AUTOSAR XML (schema 00048)
package /VehicleProject
  system System
package /Diagnostics
  diagnostic service table DS_ABT_1_MIB_ab_Gen3: ecu-instance=ABT_1_MIB_ab_Gen3
    diagnostic-connections:
      DC_DIA_ABT_1_oABT_1_MIB_ab_Gen3_oMIBCAN
      DC_Diag_ABT_1_oABT_1_MIB_ab_Gen3_oMIBCAN
      DC_HID_ABT_1_ZR_oICC_IO_Node_oMIBCAN
      {diagnostic-connection=DC_HID_ABT_1_ZR_oZR_MIB_EINSTIEG_ab_Gen3_oMIBCAN, variation-point=post-build-variant-condition{matching-criterion=Communication, value=0}}
      {diagnostic-connection=DC_HID_ABT_1_ZR_oZR_MIB_OPTION_ab_Gen3_oMIBCAN, variation-point=post-build-variant-condition{matching-criterion=Communication, value=0}}
      DC_HID_ZR_ABT_1_oABT_1_MIB_ab_Gen3_oMIBCAN
      DC_KS_SSN_ABT_1_oABT_1_MIB_ab_Gen3_oMIBCAN
      DC_OBDC_SSN_ABT_1_oABT_1_MIB_ab_Gen3_oMIBCAN
      {diagnostic-connection=DC_HID_ABT_1_ZR_oICAS3_Gateway_oMIBCAN, variation-point=post-build-variant-condition{matching-criterion=Communication, value=1}}
      {diagnostic-connection=DC_HID_ABT_1_ZR_oZR_MIB_TOP_ab_Gen3_oMIBCAN, variation-point=post-build-variant-condition{matching-criterion=Communication, value=1}}
  10 x diagnostic connection:
    DC_DIA_ABT_1_oABT_1_MIB_ab_Gen3_oMIBCAN: physical-request=MIBCAN/DIA_ABT_1_Req_oTN_ABT_1_MIB_ab_Gen3, response=MIBCAN/DIA_ABT_1_Resp_oTN_ABT_1_MIB_ab_Gen3
    DC_Diag_ABT_1_oABT_1_MIB_ab_Gen3_oMIBCAN: physical-request=MIBCAN/Diag_ABT_1_Req_oTN_ABT_1_MIB_ab_Gen3, response=MIBCAN/Diag_ABT_1_Resp_oTN_ABT_1_MIB_ab_Gen3
    DC_HID_ABT_1_ZR_oICC_IO_Node_oMIBCAN: physical-request=MIBCAN/HID_ABT_1_ZR_Req_oTN_ICC_IO_Node, response=MIBCAN/HID_ABT_1_ZR_Resp_oTN_ICC_IO_Node
    DC_HID_ABT_1_ZR_oZR_MIB_EINSTIEG_ab_Gen3_oMIBCAN: physical-request=HID_ABT_1_ZR_Req_oTN_ZR_MIB_EINSTIEG_ab_Gen3, response=HID_ABT_1_ZR_Resp_oTN_ZR_MIB_EINSTIEG_ab_Gen3
    DC_HID_ABT_1_ZR_oZR_MIB_OPTION_ab_Gen3_oMIBCAN: physical-request=HID_ABT_1_ZR_Req_oTN_ZR_MIB_OPTION_ab_Gen3, response=HID_ABT_1_ZR_Resp_oTN_ZR_MIB_OPTION_ab_Gen3
    DC_HID_ZR_ABT_1_oABT_1_MIB_ab_Gen3_oMIBCAN: physical-request=MIBCAN/HID_ZR_ABT_1_Req_oTN_ABT_1_MIB_ab_Gen3, response=MIBCAN/HID_ZR_ABT_1_Resp_oTN_ABT_1_MIB_ab_Gen3
    DC_KS_SSN_ABT_1_oABT_1_MIB_ab_Gen3_oMIBCAN: physical-request=MIBCAN/KS_SSN_ABT_1_Req_oTN_ABT_1_MIB_ab_Gen3, response=MIBCAN/KS_SSN_ABT_1_Resp_oTN_ABT_1_MIB_ab_Gen3
    DC_OBDC_SSN_ABT_1_oABT_1_MIB_ab_Gen3_oMIBCAN: physical-request=MIBCAN/OBDC_SSN_ABT_1_Req_oTN_ABT_1_MIB_ab_Gen3, response=MIBCAN/OBDC_SSN_ABT_1_Resp_oTN_ABT_1_MIB_ab_Gen3
    DC_HID_ABT_1_ZR_oICAS3_Gateway_oMIBCAN: physical-request=HID_ABT_1_ZR_Req_oTN_ICAS3_Gateway, response=HID_ABT_1_ZR_Resp_oTN_ICAS3_Gateway
    DC_HID_ABT_1_ZR_oZR_MIB_TOP_ab_Gen3_oMIBCAN: physical-request=HID_ABT_1_ZR_Req_oTN_ZR_MIB_TOP_ab_Gen3, response=HID_ABT_1_ZR_Resp_oTN_ZR_MIB_TOP_ab_Gen3
package /NM
  nm config NmConfig: can-nm-cluster-coupling=coupled-cluster=MIBCAN
    can nm cluster MIBCAN: communication-cluster=MIBCAN, nm-channel-id=0, nm-cbv-position=1, nm-network-timeout=1, nm-nid-position=0, nm-user-data-length=6, nm-wait-bus-sleep-time=0.75
      22 x can nm node, all with nm-range-config={lower-can-id=452984832, upper-can-id=452985087}:
        ABT_1_MIB_ab_Gen3: controller=CT_MIBCAN, nm-if-ecu=ABT_1_MIB_ab_Gen3_CAN, nm-node-id=241, rx-nm-pdu=[NMH_DU_1_oMIBCAN, NMH_DU_2_oMIBCAN, NMH_Info_El_oMIBCAN, NMH_LSR_1_oMIBCAN, NMH_WLC1_oMIBCAN], tx-nm-pdu=NMH_ABT_1_oMIBCAN, variation-point=post-build-variant-condition{matching-criterion=Communication, value=0}
        DU_1_MQB: nm-if-ecu=DU_1_MQB_CAN, nm-node-id=242, rx-nm-pdu=[NMH_ABT_1_oMIBCAN, NMH_DU_2_oMIBCAN, NMH_Info_El_oMIBCAN, NMH_LSR_1_oMIBCAN, NMH_WLC1_oMIBCAN], tx-nm-pdu=NMH_DU_1_oMIBCAN, variation-point=post-build-variant-condition{matching-criterion=Communication, value=0}
        DU_2: nm-if-ecu=DU_2_CAN, nm-node-id=245, rx-nm-pdu=[NMH_ABT_1_oMIBCAN, NMH_DU_1_oMIBCAN, NMH_Info_El_oMIBCAN, NMH_LSR_1_oMIBCAN, NMH_WLC1_oMIBCAN], tx-nm-pdu=NMH_DU_2_oMIBCAN, variation-point=post-build-variant-condition{matching-criterion=Communication, value=0}
        ICC_IO_Node: nm-if-ecu=ICC_IO_Node_CAN, nm-node-id=115, rx-nm-pdu=[NMH_ABT_1_oMIBCAN, NMH_DU_1_oMIBCAN, NMH_DU_2_oMIBCAN, NMH_LSR_1_oMIBCAN, NMH_WLC1_oMIBCAN], tx-nm-pdu=NMH_Info_El_oMIBCAN, variation-point=post-build-variant-condition{matching-criterion=Communication, value=0}
        LSR_1: nm-if-ecu=LSR_1_CAN, nm-node-id=246, rx-nm-pdu=[NMH_ABT_1_oMIBCAN, NMH_DU_1_oMIBCAN, NMH_DU_2_oMIBCAN, NMH_Info_El_oMIBCAN, NMH_WLC1_oMIBCAN], tx-nm-pdu=NMH_LSR_1_oMIBCAN, variation-point=post-build-variant-condition{matching-criterion=Communication, value=0}
        Sound_MIB_ab_Gen3: nm-if-ecu=Sound_MIB_ab_Gen3_CAN, nm-node-id=0, nm-passive-mode-enabled=true, rx-nm-pdu=[NMH_ABT_1_oMIBCAN, NMH_DU_1_oMIBCAN, NMH_DU_2_oMIBCAN, NMH_Info_El_oMIBCAN, NMH_LSR_1_oMIBCAN, NMH_WLC1_oMIBCAN], variation-point=post-build-variant-condition{matching-criterion=Communication, value=0}
        TVTuner_ab_Gen3_JPN: nm-if-ecu=TVTuner_ab_Gen3_JPN_CAN, nm-node-id=0, nm-passive-mode-enabled=true, rx-nm-pdu=[NMH_ABT_1_oMIBCAN, NMH_DU_1_oMIBCAN, NMH_DU_2_oMIBCAN, NMH_Info_El_oMIBCAN, NMH_LSR_1_oMIBCAN, NMH_WLC1_oMIBCAN], variation-point=post-build-variant-condition{matching-criterion=Communication, value=0}
        WLC_01: nm-if-ecu=WLC_01_CAN, nm-node-id=165, rx-nm-pdu=[NMH_ABT_1_oMIBCAN, NMH_DU_1_oMIBCAN, NMH_DU_2_oMIBCAN, NMH_Info_El_oMIBCAN, NMH_LSR_1_oMIBCAN], tx-nm-pdu=NMH_WLC1_oMIBCAN, variation-point=post-build-variant-condition{matching-criterion=Communication, value=0}
        ZR_MIB_EINSTIEG_ab_Gen3: nm-if-ecu=ZR_MIB_EINSTIEG_ab_Gen3_CAN, nm-node-id=115, rx-nm-pdu=[NMH_ABT_1_oMIBCAN, NMH_DU_1_oMIBCAN, NMH_DU_2_oMIBCAN, NMH_LSR_1_oMIBCAN, NMH_WLC1_oMIBCAN], tx-nm-pdu=NMH_Info_El_oMIBCAN, variation-point=post-build-variant-condition{matching-criterion=Communication, value=0}
        ZR_MIB_OPTION_ab_Gen3: nm-if-ecu=ZR_MIB_OPTION_ab_Gen3_CAN, nm-node-id=115, rx-nm-pdu=[NMH_ABT_1_oMIBCAN, NMH_DU_1_oMIBCAN, NMH_DU_2_oMIBCAN, NMH_LSR_1_oMIBCAN, NMH_WLC1_oMIBCAN], tx-nm-pdu=NMH_Info_El_oMIBCAN, variation-point=post-build-variant-condition{matching-criterion=Communication, value=0}
        ZR_MIB_TOP_ab_Gen3: nm-if-ecu=ZR_MIB_TOP_ab_Gen3_CAN, nm-node-id=115, rx-nm-pdu=[NMH_ABT_1_oMIBCAN, NMH_DU_1_oMIBCAN, NMH_DU_2_oMIBCAN, NMH_LSR_1_oMIBCAN, NMH_WLC1_oMIBCAN], tx-nm-pdu=NMH_Info_El_oMIBCAN, variation-point=post-build-variant-condition{matching-criterion=Communication, value=0}
        ABT_1_MIB_ab_Gen3: controller=CT_MIBCAN, nm-if-ecu=ABT_1_MIB_ab_Gen3_CAN, nm-node-id=241, rx-nm-pdu=[NMH_DU_1_oMIBCAN, NMH_DU_2_oMIBCAN, NMH_DU_3_oMIBCAN, NMH_Info_El_oMIBCAN, NMH_LSR_1_oMIBCAN, NMH_WLC1_oMIBCAN], tx-nm-pdu=NMH_ABT_1_oMIBCAN, variation-point=post-build-variant-condition{matching-criterion=Communication, value=1}
        DU_1_MQB: nm-if-ecu=DU_1_MQB_CAN, nm-node-id=242, rx-nm-pdu=[NMH_ABT_1_oMIBCAN, NMH_DU_2_oMIBCAN, NMH_DU_3_oMIBCAN, NMH_Info_El_oMIBCAN, NMH_LSR_1_oMIBCAN, NMH_WLC1_oMIBCAN], tx-nm-pdu=NMH_DU_1_oMIBCAN, variation-point=post-build-variant-condition{matching-criterion=Communication, value=1}
        DU_2: nm-if-ecu=DU_2_CAN, nm-node-id=245, rx-nm-pdu=[NMH_ABT_1_oMIBCAN, NMH_DU_1_oMIBCAN, NMH_DU_3_oMIBCAN, NMH_Info_El_oMIBCAN, NMH_LSR_1_oMIBCAN, NMH_WLC1_oMIBCAN], tx-nm-pdu=NMH_DU_2_oMIBCAN, variation-point=post-build-variant-condition{matching-criterion=Communication, value=1}
        DU_3: nm-if-ecu=DU_3_CAN, nm-node-id=254, rx-nm-pdu=[NMH_ABT_1_oMIBCAN, NMH_DU_1_oMIBCAN, NMH_DU_2_oMIBCAN, NMH_Info_El_oMIBCAN, NMH_LSR_1_oMIBCAN, NMH_WLC1_oMIBCAN], tx-nm-pdu=NMH_DU_3_oMIBCAN, variation-point=post-build-variant-condition{matching-criterion=Communication, value=1}
        ICAS3_Gateway: nm-if-ecu=ICAS3_Gateway_CAN, nm-node-id=115, rx-nm-pdu=[NMH_ABT_1_oMIBCAN, NMH_DU_1_oMIBCAN, NMH_DU_2_oMIBCAN, NMH_DU_3_oMIBCAN, NMH_LSR_1_oMIBCAN, NMH_WLC1_oMIBCAN], tx-nm-pdu=NMH_Info_El_oMIBCAN, variation-point=post-build-variant-condition{matching-criterion=Communication, value=1}
        ICC_IO_Node: nm-if-ecu=ICC_IO_Node_CAN, nm-node-id=115, rx-nm-pdu=[NMH_ABT_1_oMIBCAN, NMH_DU_1_oMIBCAN, NMH_DU_2_oMIBCAN, NMH_DU_3_oMIBCAN, NMH_LSR_1_oMIBCAN, NMH_WLC1_oMIBCAN], tx-nm-pdu=NMH_Info_El_oMIBCAN, variation-point=post-build-variant-condition{matching-criterion=Communication, value=1}
        LSR_1: nm-if-ecu=LSR_1_CAN, nm-node-id=246, rx-nm-pdu=[NMH_ABT_1_oMIBCAN, NMH_DU_1_oMIBCAN, NMH_DU_2_oMIBCAN, NMH_DU_3_oMIBCAN, NMH_Info_El_oMIBCAN, NMH_WLC1_oMIBCAN], tx-nm-pdu=NMH_LSR_1_oMIBCAN, variation-point=post-build-variant-condition{matching-criterion=Communication, value=1}
        Sound_MIB_ab_Gen3: nm-if-ecu=Sound_MIB_ab_Gen3_CAN, nm-node-id=0, nm-passive-mode-enabled=true, rx-nm-pdu=[NMH_ABT_1_oMIBCAN, NMH_DU_1_oMIBCAN, NMH_DU_2_oMIBCAN, NMH_DU_3_oMIBCAN, NMH_Info_El_oMIBCAN, NMH_LSR_1_oMIBCAN, NMH_WLC1_oMIBCAN], variation-point=post-build-variant-condition{matching-criterion=Communication, value=1}
        TVTuner_ab_Gen3_JPN: nm-if-ecu=TVTuner_ab_Gen3_JPN_CAN, nm-node-id=0, nm-passive-mode-enabled=true, rx-nm-pdu=[NMH_ABT_1_oMIBCAN, NMH_DU_1_oMIBCAN, NMH_DU_2_oMIBCAN, NMH_DU_3_oMIBCAN, NMH_Info_El_oMIBCAN, NMH_LSR_1_oMIBCAN, NMH_WLC1_oMIBCAN], variation-point=post-build-variant-condition{matching-criterion=Communication, value=1}
        WLC_01: nm-if-ecu=WLC_01_CAN, nm-node-id=165, rx-nm-pdu=[NMH_ABT_1_oMIBCAN, NMH_DU_1_oMIBCAN, NMH_DU_2_oMIBCAN, NMH_DU_3_oMIBCAN, NMH_Info_El_oMIBCAN, NMH_LSR_1_oMIBCAN], tx-nm-pdu=NMH_WLC1_oMIBCAN, variation-point=post-build-variant-condition{matching-criterion=Communication, value=1}
        ZR_MIB_TOP_ab_Gen3: nm-if-ecu=ZR_MIB_TOP_ab_Gen3_CAN, nm-node-id=115, rx-nm-pdu=[NMH_ABT_1_oMIBCAN, NMH_DU_1_oMIBCAN, NMH_DU_2_oMIBCAN, NMH_DU_3_oMIBCAN, NMH_LSR_1_oMIBCAN, NMH_WLC1_oMIBCAN], tx-nm-pdu=NMH_Info_El_oMIBCAN, variation-point=post-build-variant-condition{matching-criterion=Communication, value=1}
    nm-if-ecus:
      13 x nm ecu, all with nm-node-id-enabled=true, nm-user-data-enabled=true:
        ABT_1_MIB_ab_Gen3_CAN: ecu-instance=ABT_1_MIB_ab_Gen3
        DU_1_MQB_CAN
        DU_2_CAN
        ICC_IO_Node_CAN
        LSR_1_CAN
        Sound_MIB_ab_Gen3_CAN: nm-passive-mode-enabled=true
        TVTuner_ab_Gen3_JPN_CAN: nm-passive-mode-enabled=true
        WLC_01_CAN
        ZR_MIB_EINSTIEG_ab_Gen3_CAN: variation-point=post-build-variant-condition{matching-criterion=Communication, value=0}
        ZR_MIB_OPTION_ab_Gen3_CAN: variation-point=post-build-variant-condition{matching-criterion=Communication, value=0}
        ZR_MIB_TOP_ab_Gen3_CAN
        DU_3_CAN: variation-point=post-build-variant-condition{matching-criterion=Communication, value=1}
        ICAS3_Gateway_CAN: variation-point=post-build-variant-condition{matching-criterion=Communication, value=1}
package /TP
  can tp config MIBCAN: communication-cluster=MIBCAN, can-tp-ecu{cycle-time-main-function=0.005, ecu-instance=ABT_1_MIB_ab_Gen3}
    can tp channel TPCH: channel-id=0, channel-mode=FULL-DUPLEX-MODE
    can-tp-connection addressing-format=STANDARD, can-tp-channel=TPCH, data-pdu=DIA_ABT_1_Req_Tp_oMIBCAN, flow-control-pdu=DIA_ABT_1_Resp_Tp_oMIBCAN, receiver=TN_ABT_1_MIB_ab_Gen3, ta-type=PHYSICAL, tp-sdu=DIA_ABT_1_Req_oMIBCAN, transmitter=TN_ICC_IO_Node, variation-point=post-build-variant-condition{matching-criterion=Communication, value=0}:
      ident DIA_ABT_1_Req_oTN_ABT_1_MIB_ab_Gen3
    can-tp-connection addressing-format=STANDARD, can-tp-channel=TPCH, data-pdu=DIA_ABT_1_Resp_Tp_oMIBCAN, flow-control-pdu=DIA_ABT_1_Req_Tp_oMIBCAN, receiver=TN_ICC_IO_Node, ta-type=PHYSICAL, tp-sdu=DIA_ABT_1_Resp_oMIBCAN, transmitter=TN_ABT_1_MIB_ab_Gen3, variation-point=post-build-variant-condition{matching-criterion=Communication, value=0}:
      ident DIA_ABT_1_Resp_oTN_ABT_1_MIB_ab_Gen3
    can-tp-connection addressing-format=STANDARD, can-tp-channel=TPCH, data-pdu=Diag_ABT_1_Req_Tp_oMIBCAN, flow-control-pdu=Diag_ABT_1_Resp_Tp_oMIBCAN, receiver=TN_ABT_1_MIB_ab_Gen3, ta-type=PHYSICAL, tp-sdu=Diag_ABT_1_Req_oMIBCAN, transmitter=TN_ICC_IO_Node, variation-point=post-build-variant-condition{matching-criterion=Communication, value=0}:
      ident Diag_ABT_1_Req_oTN_ABT_1_MIB_ab_Gen3
    can-tp-connection addressing-format=STANDARD, can-tp-channel=TPCH, data-pdu=Diag_ABT_1_Resp_Tp_oMIBCAN, flow-control-pdu=Diag_ABT_1_Req_Tp_oMIBCAN, receiver=TN_ICC_IO_Node, ta-type=PHYSICAL, tp-sdu=Diag_ABT_1_Resp_oMIBCAN, transmitter=TN_ABT_1_MIB_ab_Gen3, variation-point=post-build-variant-condition{matching-criterion=Communication, value=0}:
      ident Diag_ABT_1_Resp_oTN_ABT_1_MIB_ab_Gen3
    can-tp-connection addressing-format=STANDARD, can-tp-channel=TPCH, data-pdu=HID_ABT_1_ZR_Req_Tp_oMIBCAN, flow-control-pdu=HID_ABT_1_ZR_Resp_Tp_oMIBCAN, receiver=TN_ICC_IO_Node, ta-type=PHYSICAL, tp-sdu=HID_ABT_1_ZR_Req_oMIBCAN, transmitter=TN_ABT_1_MIB_ab_Gen3, variation-point=post-build-variant-condition{matching-criterion=Communication, value=0}:
      ident HID_ABT_1_ZR_Req_oTN_ICC_IO_Node
    can-tp-connection addressing-format=STANDARD, can-tp-channel=TPCH, data-pdu=HID_ABT_1_ZR_Req_Tp_oMIBCAN, flow-control-pdu=HID_ABT_1_ZR_Resp_Tp_oMIBCAN, receiver=TN_ZR_MIB_EINSTIEG_ab_Gen3, ta-type=PHYSICAL, tp-sdu=HID_ABT_1_ZR_Req_oMIBCAN, transmitter=TN_ABT_1_MIB_ab_Gen3, variation-point=post-build-variant-condition{matching-criterion=Communication, value=0}:
      ident HID_ABT_1_ZR_Req_oTN_ZR_MIB_EINSTIEG_ab_Gen3
    can-tp-connection addressing-format=STANDARD, can-tp-channel=TPCH, data-pdu=HID_ABT_1_ZR_Req_Tp_oMIBCAN, flow-control-pdu=HID_ABT_1_ZR_Resp_Tp_oMIBCAN, receiver=TN_ZR_MIB_OPTION_ab_Gen3, ta-type=PHYSICAL, tp-sdu=HID_ABT_1_ZR_Req_oMIBCAN, transmitter=TN_ABT_1_MIB_ab_Gen3, variation-point=post-build-variant-condition{matching-criterion=Communication, value=0}:
      ident HID_ABT_1_ZR_Req_oTN_ZR_MIB_OPTION_ab_Gen3
    can-tp-connection addressing-format=STANDARD, can-tp-channel=TPCH, data-pdu=HID_ABT_1_ZR_Resp_Tp_oMIBCAN, flow-control-pdu=HID_ABT_1_ZR_Req_Tp_oMIBCAN, receiver=TN_ABT_1_MIB_ab_Gen3, ta-type=PHYSICAL, tp-sdu=HID_ABT_1_ZR_Resp_oMIBCAN, transmitter=TN_ICC_IO_Node, variation-point=post-build-variant-condition{matching-criterion=Communication, value=0}:
      ident HID_ABT_1_ZR_Resp_oTN_ICC_IO_Node
    can-tp-connection addressing-format=STANDARD, can-tp-channel=TPCH, data-pdu=HID_ABT_1_ZR_Resp_Tp_oMIBCAN, flow-control-pdu=HID_ABT_1_ZR_Req_Tp_oMIBCAN, receiver=TN_ABT_1_MIB_ab_Gen3, ta-type=PHYSICAL, tp-sdu=HID_ABT_1_ZR_Resp_oMIBCAN, transmitter=TN_ZR_MIB_EINSTIEG_ab_Gen3, variation-point=post-build-variant-condition{matching-criterion=Communication, value=0}:
      ident HID_ABT_1_ZR_Resp_oTN_ZR_MIB_EINSTIEG_ab_Gen3
    can-tp-connection addressing-format=STANDARD, can-tp-channel=TPCH, data-pdu=HID_ABT_1_ZR_Resp_Tp_oMIBCAN, flow-control-pdu=HID_ABT_1_ZR_Req_Tp_oMIBCAN, receiver=TN_ABT_1_MIB_ab_Gen3, ta-type=PHYSICAL, tp-sdu=HID_ABT_1_ZR_Resp_oMIBCAN, transmitter=TN_ZR_MIB_OPTION_ab_Gen3, variation-point=post-build-variant-condition{matching-criterion=Communication, value=0}:
      ident HID_ABT_1_ZR_Resp_oTN_ZR_MIB_OPTION_ab_Gen3
    can-tp-connection addressing-format=STANDARD, can-tp-channel=TPCH, data-pdu=HID_ZR_ABT_1_Req_Tp_oMIBCAN, flow-control-pdu=HID_ZR_ABT_1_Resp_Tp_oMIBCAN, receiver=TN_ABT_1_MIB_ab_Gen3, ta-type=PHYSICAL, tp-sdu=HID_ZR_ABT_1_Req_oMIBCAN, transmitter=TN_ICC_IO_Node, variation-point=post-build-variant-condition{matching-criterion=Communication, value=0}:
      ident HID_ZR_ABT_1_Req_oTN_ABT_1_MIB_ab_Gen3
    can-tp-connection addressing-format=STANDARD, can-tp-channel=TPCH, data-pdu=HID_ZR_ABT_1_Resp_Tp_oMIBCAN, flow-control-pdu=HID_ZR_ABT_1_Req_Tp_oMIBCAN, receiver=TN_ICC_IO_Node, ta-type=PHYSICAL, tp-sdu=HID_ZR_ABT_1_Resp_oMIBCAN, transmitter=TN_ABT_1_MIB_ab_Gen3, variation-point=post-build-variant-condition{matching-criterion=Communication, value=0}:
      ident HID_ZR_ABT_1_Resp_oTN_ABT_1_MIB_ab_Gen3
    can-tp-connection addressing-format=STANDARD, can-tp-channel=TPCH, data-pdu=KS_SSN_ABT_1_Req_Tp_oMIBCAN, flow-control-pdu=KS_SSN_ABT_1_Resp_Tp_oMIBCAN, receiver=TN_ABT_1_MIB_ab_Gen3, ta-type=PHYSICAL, tp-sdu=KS_SSN_ABT_1_Req_oMIBCAN, transmitter=TN_ICC_IO_Node, variation-point=post-build-variant-condition{matching-criterion=Communication, value=0}:
      ident KS_SSN_ABT_1_Req_oTN_ABT_1_MIB_ab_Gen3
    can-tp-connection addressing-format=STANDARD, can-tp-channel=TPCH, data-pdu=KS_SSN_ABT_1_Resp_Tp_oMIBCAN, flow-control-pdu=KS_SSN_ABT_1_Req_Tp_oMIBCAN, receiver=TN_ICC_IO_Node, ta-type=PHYSICAL, tp-sdu=KS_SSN_ABT_1_Resp_oMIBCAN, transmitter=TN_ABT_1_MIB_ab_Gen3, variation-point=post-build-variant-condition{matching-criterion=Communication, value=0}:
      ident KS_SSN_ABT_1_Resp_oTN_ABT_1_MIB_ab_Gen3
    can-tp-connection addressing-format=STANDARD, can-tp-channel=TPCH, data-pdu=OBDC_SSN_ABT_1_Req_Tp_oMIBCAN, flow-control-pdu=OBDC_SSN_ABT_1_Resp_Tp_oMIBCAN, receiver=TN_ABT_1_MIB_ab_Gen3, ta-type=PHYSICAL, tp-sdu=OBDC_SSN_ABT_1_Req_oMIBCAN, transmitter=TN_ICC_IO_Node, variation-point=post-build-variant-condition{matching-criterion=Communication, value=0}:
      ident OBDC_SSN_ABT_1_Req_oTN_ABT_1_MIB_ab_Gen3
    can-tp-connection addressing-format=STANDARD, can-tp-channel=TPCH, data-pdu=OBDC_SSN_ABT_1_Resp_Tp_oMIBCAN, flow-control-pdu=OBDC_SSN_ABT_1_Req_Tp_oMIBCAN, receiver=TN_ICC_IO_Node, ta-type=PHYSICAL, tp-sdu=OBDC_SSN_ABT_1_Resp_oMIBCAN, transmitter=TN_ABT_1_MIB_ab_Gen3, variation-point=post-build-variant-condition{matching-criterion=Communication, value=0}:
      ident OBDC_SSN_ABT_1_Resp_oTN_ABT_1_MIB_ab_Gen3
    can-tp-connection addressing-format=STANDARD, can-tp-channel=TPCH, data-pdu=DIA_ABT_1_Req_Tp_oMIBCAN, flow-control-pdu=DIA_ABT_1_Resp_Tp_oMIBCAN, receiver=TN_ABT_1_MIB_ab_Gen3, ta-type=PHYSICAL, tp-sdu=DIA_ABT_1_Req_oMIBCAN, transmitter=TN_ICAS3_Gateway, variation-point=post-build-variant-condition{matching-criterion=Communication, value=1}:
      ident DIA_ABT_1_Req_oTN_ABT_1_MIB_ab_Gen3
    can-tp-connection addressing-format=STANDARD, can-tp-channel=TPCH, data-pdu=DIA_ABT_1_Resp_Tp_oMIBCAN, flow-control-pdu=DIA_ABT_1_Req_Tp_oMIBCAN, receiver=TN_ICAS3_Gateway, ta-type=PHYSICAL, tp-sdu=DIA_ABT_1_Resp_oMIBCAN, transmitter=TN_ABT_1_MIB_ab_Gen3, variation-point=post-build-variant-condition{matching-criterion=Communication, value=1}:
      ident DIA_ABT_1_Resp_oTN_ABT_1_MIB_ab_Gen3
    can-tp-connection addressing-format=STANDARD, can-tp-channel=TPCH, data-pdu=Diag_ABT_1_Req_Tp_oMIBCAN, flow-control-pdu=Diag_ABT_1_Resp_Tp_oMIBCAN, receiver=TN_ABT_1_MIB_ab_Gen3, ta-type=PHYSICAL, tp-sdu=Diag_ABT_1_Req_oMIBCAN, transmitter=TN_ICAS3_Gateway, variation-point=post-build-variant-condition{matching-criterion=Communication, value=1}:
      ident Diag_ABT_1_Req_oTN_ABT_1_MIB_ab_Gen3
    can-tp-connection addressing-format=STANDARD, can-tp-channel=TPCH, data-pdu=Diag_ABT_1_Resp_Tp_oMIBCAN, flow-control-pdu=Diag_ABT_1_Req_Tp_oMIBCAN, receiver=TN_ICAS3_Gateway, ta-type=PHYSICAL, tp-sdu=Diag_ABT_1_Resp_oMIBCAN, transmitter=TN_ABT_1_MIB_ab_Gen3, variation-point=post-build-variant-condition{matching-criterion=Communication, value=1}:
      ident Diag_ABT_1_Resp_oTN_ABT_1_MIB_ab_Gen3
    can-tp-connection addressing-format=STANDARD, can-tp-channel=TPCH, data-pdu=HID_ABT_1_ZR_Req_Tp_oMIBCAN, flow-control-pdu=HID_ABT_1_ZR_Resp_Tp_oMIBCAN, receiver=TN_ICAS3_Gateway, ta-type=PHYSICAL, tp-sdu=HID_ABT_1_ZR_Req_oMIBCAN, transmitter=TN_ABT_1_MIB_ab_Gen3, variation-point=post-build-variant-condition{matching-criterion=Communication, value=1}:
      ident HID_ABT_1_ZR_Req_oTN_ICAS3_Gateway
    can-tp-connection addressing-format=STANDARD, can-tp-channel=TPCH, data-pdu=HID_ABT_1_ZR_Req_Tp_oMIBCAN, flow-control-pdu=HID_ABT_1_ZR_Resp_Tp_oMIBCAN, receiver=TN_ICC_IO_Node, ta-type=PHYSICAL, tp-sdu=HID_ABT_1_ZR_Req_oMIBCAN, transmitter=TN_ABT_1_MIB_ab_Gen3, variation-point=post-build-variant-condition{matching-criterion=Communication, value=1}:
      ident HID_ABT_1_ZR_Req_oTN_ICC_IO_Node
    can-tp-connection addressing-format=STANDARD, can-tp-channel=TPCH, data-pdu=HID_ABT_1_ZR_Req_Tp_oMIBCAN, flow-control-pdu=HID_ABT_1_ZR_Resp_Tp_oMIBCAN, receiver=TN_ZR_MIB_TOP_ab_Gen3, ta-type=PHYSICAL, tp-sdu=HID_ABT_1_ZR_Req_oMIBCAN, transmitter=TN_ABT_1_MIB_ab_Gen3, variation-point=post-build-variant-condition{matching-criterion=Communication, value=1}:
      ident HID_ABT_1_ZR_Req_oTN_ZR_MIB_TOP_ab_Gen3
    can-tp-connection addressing-format=STANDARD, can-tp-channel=TPCH, data-pdu=HID_ABT_1_ZR_Resp_Tp_oMIBCAN, flow-control-pdu=HID_ABT_1_ZR_Req_Tp_oMIBCAN, receiver=TN_ABT_1_MIB_ab_Gen3, ta-type=PHYSICAL, tp-sdu=HID_ABT_1_ZR_Resp_oMIBCAN, transmitter=TN_ICAS3_Gateway, variation-point=post-build-variant-condition{matching-criterion=Communication, value=1}:
      ident HID_ABT_1_ZR_Resp_oTN_ICAS3_Gateway
    can-tp-connection addressing-format=STANDARD, can-tp-channel=TPCH, data-pdu=HID_ABT_1_ZR_Resp_Tp_oMIBCAN, flow-control-pdu=HID_ABT_1_ZR_Req_Tp_oMIBCAN, receiver=TN_ABT_1_MIB_ab_Gen3, ta-type=PHYSICAL, tp-sdu=HID_ABT_1_ZR_Resp_oMIBCAN, transmitter=TN_ICC_IO_Node, variation-point=post-build-variant-condition{matching-criterion=Communication, value=1}:
      ident HID_ABT_1_ZR_Resp_oTN_ICC_IO_Node
    can-tp-connection addressing-format=STANDARD, can-tp-channel=TPCH, data-pdu=HID_ABT_1_ZR_Resp_Tp_oMIBCAN, flow-control-pdu=HID_ABT_1_ZR_Req_Tp_oMIBCAN, receiver=TN_ABT_1_MIB_ab_Gen3, ta-type=PHYSICAL, tp-sdu=HID_ABT_1_ZR_Resp_oMIBCAN, transmitter=TN_ZR_MIB_TOP_ab_Gen3, variation-point=post-build-variant-condition{matching-criterion=Communication, value=1}:
      ident HID_ABT_1_ZR_Resp_oTN_ZR_MIB_TOP_ab_Gen3
    can-tp-connection addressing-format=STANDARD, can-tp-channel=TPCH, data-pdu=HID_ZR_ABT_1_Req_Tp_oMIBCAN, flow-control-pdu=HID_ZR_ABT_1_Resp_Tp_oMIBCAN, receiver=TN_ABT_1_MIB_ab_Gen3, ta-type=PHYSICAL, tp-sdu=HID_ZR_ABT_1_Req_oMIBCAN, transmitter=TN_ICAS3_Gateway, variation-point=post-build-variant-condition{matching-criterion=Communication, value=1}:
      ident HID_ZR_ABT_1_Req_oTN_ABT_1_MIB_ab_Gen3
    can-tp-connection addressing-format=STANDARD, can-tp-channel=TPCH, data-pdu=HID_ZR_ABT_1_Resp_Tp_oMIBCAN, flow-control-pdu=HID_ZR_ABT_1_Req_Tp_oMIBCAN, receiver=TN_ICAS3_Gateway, ta-type=PHYSICAL, tp-sdu=HID_ZR_ABT_1_Resp_oMIBCAN, transmitter=TN_ABT_1_MIB_ab_Gen3, variation-point=post-build-variant-condition{matching-criterion=Communication, value=1}:
      ident HID_ZR_ABT_1_Resp_oTN_ABT_1_MIB_ab_Gen3
    can-tp-connection addressing-format=STANDARD, can-tp-channel=TPCH, data-pdu=KS_SSN_ABT_1_Req_Tp_oMIBCAN, flow-control-pdu=KS_SSN_ABT_1_Resp_Tp_oMIBCAN, receiver=TN_ABT_1_MIB_ab_Gen3, ta-type=PHYSICAL, tp-sdu=KS_SSN_ABT_1_Req_oMIBCAN, transmitter=TN_ICAS3_Gateway, variation-point=post-build-variant-condition{matching-criterion=Communication, value=1}:
      ident KS_SSN_ABT_1_Req_oTN_ABT_1_MIB_ab_Gen3
    can-tp-connection addressing-format=STANDARD, can-tp-channel=TPCH, data-pdu=KS_SSN_ABT_1_Resp_Tp_oMIBCAN, flow-control-pdu=KS_SSN_ABT_1_Req_Tp_oMIBCAN, receiver=TN_ICAS3_Gateway, ta-type=PHYSICAL, tp-sdu=KS_SSN_ABT_1_Resp_oMIBCAN, transmitter=TN_ABT_1_MIB_ab_Gen3, variation-point=post-build-variant-condition{matching-criterion=Communication, value=1}:
      ident KS_SSN_ABT_1_Resp_oTN_ABT_1_MIB_ab_Gen3
    can-tp-connection addressing-format=STANDARD, can-tp-channel=TPCH, data-pdu=OBDC_SSN_ABT_1_Req_Tp_oMIBCAN, flow-control-pdu=OBDC_SSN_ABT_1_Resp_Tp_oMIBCAN, receiver=TN_ABT_1_MIB_ab_Gen3, ta-type=PHYSICAL, tp-sdu=OBDC_SSN_ABT_1_Req_oMIBCAN, transmitter=TN_ICAS3_Gateway, variation-point=post-build-variant-condition{matching-criterion=Communication, value=1}:
      ident OBDC_SSN_ABT_1_Req_oTN_ABT_1_MIB_ab_Gen3
    can-tp-connection addressing-format=STANDARD, can-tp-channel=TPCH, data-pdu=OBDC_SSN_ABT_1_Resp_Tp_oMIBCAN, flow-control-pdu=OBDC_SSN_ABT_1_Req_Tp_oMIBCAN, receiver=TN_ICAS3_Gateway, ta-type=PHYSICAL, tp-sdu=OBDC_SSN_ABT_1_Resp_oMIBCAN, transmitter=TN_ABT_1_MIB_ab_Gen3, variation-point=post-build-variant-condition{matching-criterion=Communication, value=1}:
      ident OBDC_SSN_ABT_1_Resp_oTN_ABT_1_MIB_ab_Gen3
    6 x can tp node:
      TN_ABT_1_MIB_ab_Gen3: connector=CN_MIBCAN
      TN_ICC_IO_Node
      TN_ZR_MIB_EINSTIEG_ab_Gen3: variation-point=post-build-variant-condition{matching-criterion=Communication, value=0}
      TN_ZR_MIB_OPTION_ab_Gen3: variation-point=post-build-variant-condition{matching-criterion=Communication, value=0}
      TN_ZR_MIB_TOP_ab_Gen3
      TN_ICAS3_Gateway: variation-point=post-build-variant-condition{matching-criterion=Communication, value=1}
package /Cluster
  can cluster MIBCAN: baudrate=500000, protocol-name=CAN  # MQBw_Baseline_MIBCAN_KMatrix_V14.08F_20220630_SK | MIBCAN_V14.08F Generated by BUSNETNG Produktiv 9.24.5
    can physical channel CHNL: comm-connectors=CN_MIBCAN
      frame BEM_02_oMIBCAN: id 0x663, to ABT_1_MIB_ab_Gen3, frame-length=8, can-addressing-mode=STANDARD  # DLC=8 ab D4 gültig
        pdu BEM_02_oMIBCAN: length=8, minimum-delay=0, transmission-mode-false-timing=cyclic-timing={time-offset=0, time-period=0.1}, transmission-mode-true-timing=cyclic-timing={time-offset=0, time-period=0.1}, unused-bit-pattern=0
          signal NVEM_Abschaltstufe_oBEM_02_oMIBCAN: start 0, 2 bit, little-endian, i-signal-type=PRIMITIVE, init-value=0, base-type=uint8, compu-method=CM_NVEM_Abschaltstufe, data-constr=DC_NVEM_Abschaltstufe, transfer-property=PENDING, to ABT_1_MIB_ab_Gen3(timeout 1 s)  # Abschaltstufe aus dem Ruheenergiemanagement Maßnahmen des Empfängers werden im QLAH Ruhestrommanagement definiert
      frame DEV_ABT_1_Gen3_Tx_01_oMIBCAN: id 0x1BFF8B0A, from ABT_1_MIB_ab_Gen3, frame-length=8, can-addressing-mode=EXTENDED
        user defined pdu DEV_ABT_1_Gen3_Tx_01_oMIBCAN: length=8
      frame DEV_ABT_1_Gen3_Tx_02_oMIBCAN: id 0x1BFF8B0B, from ABT_1_MIB_ab_Gen3, frame-length=8, can-addressing-mode=EXTENDED
        user defined pdu DEV_ABT_1_Gen3_Tx_02_oMIBCAN: length=8
      frame DEV_ABT_1_Gen3_Tx_03_oMIBCAN: id 0x1BFF8B0C, from ABT_1_MIB_ab_Gen3, frame-length=8, can-addressing-mode=EXTENDED
        user defined pdu DEV_ABT_1_Gen3_Tx_03_oMIBCAN: length=8
      frame DEV_ABT_1_Gen3_Tx_04_oMIBCAN: id 0x1BFF8B0D, from ABT_1_MIB_ab_Gen3, frame-length=8, can-addressing-mode=EXTENDED
        user defined pdu DEV_ABT_1_Gen3_Tx_04_oMIBCAN: length=8
      frame DEV_ABT_1_Req_00_oMIBCAN: id 0x1BFF8B00, to ABT_1_MIB_ab_Gen3, frame-length=8, can-addressing-mode=EXTENDED
        user defined pdu DEV_ABT_1_Req_00_oMIBCAN: length=8
      frame DEV_ABT_1_Req_04_oMIBCAN: id 0x1BFF8B04, to ABT_1_MIB_ab_Gen3, frame-length=8, can-addressing-mode=EXTENDED
        n pdu DEV_ABT_1_Req_04_Tp_oMIBCAN: length=8
      frame DEV_ABT_1_Req_05_oMIBCAN: id 0x1BFF8B0F, to ABT_1_MIB_ab_Gen3, frame-length=8, can-addressing-mode=EXTENDED
        user defined pdu DEV_ABT_1_Req_05_oMIBCAN: length=8
      frame DEV_ABT_1_Resp_01_oMIBCAN: id 0x1BFF8B01, from ABT_1_MIB_ab_Gen3, frame-length=8, can-addressing-mode=EXTENDED
        user defined pdu DEV_ABT_1_Resp_01_oMIBCAN: length=8
      frame DEV_ABT_1_Resp_02_oMIBCAN: id 0x1BFF8B02, from ABT_1_MIB_ab_Gen3, frame-length=8, can-addressing-mode=EXTENDED
        user defined pdu DEV_ABT_1_Resp_02_oMIBCAN: length=8
      frame DEV_ABT_1_Resp_03_oMIBCAN: id 0x1BFF8B03, from ABT_1_MIB_ab_Gen3, frame-length=8, can-addressing-mode=EXTENDED
        user defined pdu DEV_ABT_1_Resp_03_oMIBCAN: length=8
      frame DEV_ABT_1_Resp_04_oMIBCAN: id 0x1BFF8B05, from ABT_1_MIB_ab_Gen3, frame-length=8, can-addressing-mode=EXTENDED
        n pdu DEV_ABT_1_Resp_04_Tp_oMIBCAN: length=8
      frame DEV_ABT_1_Resp_05_oMIBCAN: id 0x1BFF8B0E, from ABT_1_MIB_ab_Gen3, frame-length=8, can-addressing-mode=EXTENDED
        user defined pdu DEV_ABT_1_Resp_05_oMIBCAN: length=8
      frame DIA_ABT_1_Req_oMIBCAN: id 0x17FC160E, to ABT_1_MIB_ab_Gen3, frame-length=8, can-addressing-mode=EXTENDED
        n pdu DIA_ABT_1_Req_Tp_oMIBCAN: length=8
      frame DIA_ABT_1_Resp_oMIBCAN: id 0x17FE160E, from ABT_1_MIB_ab_Gen3, frame-length=8, can-addressing-mode=EXTENDED
        n pdu DIA_ABT_1_Resp_Tp_oMIBCAN: length=8
      frame Diag_ABT_1_Req_oMIBCAN: id 0x17FC060E, to ABT_1_MIB_ab_Gen3, frame-length=8, can-addressing-mode=EXTENDED
        n pdu Diag_ABT_1_Req_Tp_oMIBCAN: length=8
      frame Diag_ABT_1_Resp_oMIBCAN: id 0x17FE060E, from ABT_1_MIB_ab_Gen3, frame-length=8, can-addressing-mode=EXTENDED
        n pdu Diag_ABT_1_Resp_Tp_oMIBCAN: length=8
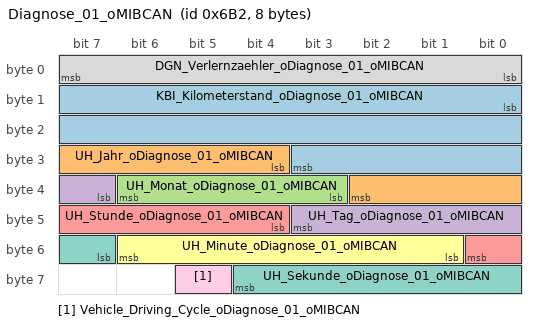
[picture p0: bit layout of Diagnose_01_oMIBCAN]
      frame Diagnose_01_oMIBCAN: id 0x6B2, to ABT_1_MIB_ab_Gen3, frame-length=8, can-addressing-mode=STANDARD
        pdu Diagnose_01_oMIBCAN: length=8, minimum-delay=0, transmission-mode-false-timing=cyclic-timing={time-offset=0, time-period=1}, transmission-mode-true-timing=cyclic-timing={time-offset=0, time-period=1}, unused-bit-pattern=0
          signal KBI_Kilometerstand_oDiagnose_01_oMIBCAN: start 8, 20 bit, little-endian, i-signal-type=PRIMITIVE, init-value=1048574, base-type=uint32, compu-method=CM_KBI_Kilometerstand, data-constr=DC_KBI_Kilometerstand, unit=Unit_KiloMeter, transfer-property=PENDING, to ABT_1_MIB_ab_Gen3(timeout 5 s)  # Fehler wird ausgegeben, falls Kilometerstand nicht restaurierbar
          signal UH_Jahr_oDiagnose_01_oMIBCAN: start 28, 7 bit, little-endian, i-signal-type=PRIMITIVE, init-value=0, base-type=uint8, compu-method=CM_UH_Jahr, data-constr=DC_UH_Jahr, unit=Unit_Year, transfer-property=PENDING, to ABT_1_MIB_ab_Gen3(timeout 5 s)
          signal UH_Monat_oDiagnose_01_oMIBCAN: start 35, 4 bit, little-endian, i-signal-type=PRIMITIVE, init-value=0, base-type=uint8, compu-method=CM_UH_Monat, data-constr=DC_UH_Monat, unit=Unit_Month, transfer-property=PENDING, to ABT_1_MIB_ab_Gen3(timeout 5 s)  # 0x0D, 0xF = Werte ungültig 0x0E = Relatives Datum (nur VW)
          signal UH_Tag_oDiagnose_01_oMIBCAN: start 39, 5 bit, little-endian, i-signal-type=PRIMITIVE, init-value=0, base-type=uint8, compu-method=CM_UH_Tag, data-constr=DC_UH_Tag, unit=Unit_Day, transfer-property=PENDING, to ABT_1_MIB_ab_Gen3(timeout 5 s)  # 0x0: reserviert bei VW
          signal UH_Stunde_oDiagnose_01_oMIBCAN: start 44, 5 bit, little-endian, i-signal-type=PRIMITIVE, init-value=0, base-type=uint8, compu-method=CM_UH_Stunde, data-constr=DC_UH_Stunde, unit=Unit_Hours, transfer-property=PENDING, to ABT_1_MIB_ab_Gen3(timeout 5 s)  # 0x18 - 0x1F = Werte ungültig
          signal UH_Minute_oDiagnose_01_oMIBCAN: start 49, 6 bit, little-endian, i-signal-type=PRIMITIVE, init-value=0, base-type=uint8, compu-method=CM_UH_Minute, data-constr=DC_UH_Minute, unit=Unit_Minut, transfer-property=PENDING, to ABT_1_MIB_ab_Gen3(timeout 5 s)  # 0x3C- 0x3f = Werte ungültig
          signal UH_Sekunde_oDiagnose_01_oMIBCAN: start 55, 6 bit, little-endian, i-signal-type=PRIMITIVE, init-value=0, base-type=uint8, compu-method=CM_UH_Sekunde, data-constr=DC_UH_Sekunde, unit=Unit_Secon, transfer-property=PENDING, to ABT_1_MIB_ab_Gen3(timeout 5 s)  # 0x3C- 0x3f = Werte ungültig
          signal DGN_Verlernzaehler_oDiagnose_01_oMIBCAN: start 0, 8 bit, little-endian, i-signal-type=PRIMITIVE, init-value=0, base-type=uint8, compu-method=CM_DGN_Verlernzaehler, data-constr=DC_DGN_Verlernzaehler, transfer-property=PENDING, variation-point=post-build-variant-condition{matching-criterion=Communication, value=1}, to ABT_1_MIB_ab_Gen3(timeout 5 s)  # wrap around 254 --> 0
          signal Vehicle_Driving_Cycle_oDiagnose_01_oMIBCAN: start 61, 1 bit, little-endian, i-signal-type=PRIMITIVE, init-value=0, base-type=boolean, compu-method=CM_Vehicle_Driving_Cycle, data-constr=DC_Vehicle_Driving_Cycle, transfer-property=PENDING, variation-point=post-build-variant-condition{matching-criterion=Communication, value=1}, to ABT_1_MIB_ab_Gen3(timeout 5 s)  # Optimierung der Inbetriebnahme von SteuergerÃ¤ten in einem Teilverbau in der Produktion. Siehe VW80114. Signal bildet (durch eine Gateway-Funktion) den Inhalt des Signals OBD_Driving_Cycle ab.
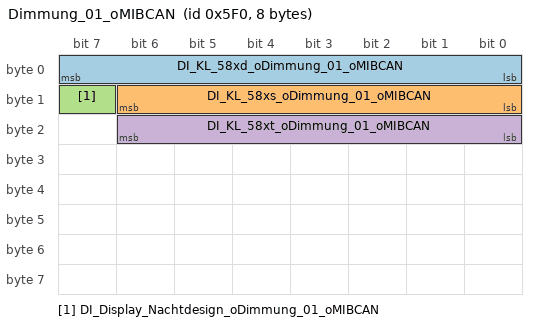
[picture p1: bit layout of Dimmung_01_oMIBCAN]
      frame Dimmung_01_oMIBCAN: id 0x5F0, to ABT_1_MIB_ab_Gen3, frame-length=8, can-addressing-mode=STANDARD  # ab MQB nach abgestimmten FLH Dimmung
        pdu Dimmung_01_oMIBCAN: length=8, minimum-delay=0.05, transmission-mode-false-timing={cyclic-timing={time-offset=0, time-period=0.2}, event-controlled-timing={number-of-repetitions=0, repetition-period=0}}, transmission-mode-true-timing={cyclic-timing={time-offset=0, time-period=0.2}, event-controlled-timing={number-of-repetitions=0, repetition-period=0}}, unused-bit-pattern=0
          signal DI_KL_58xd_oDimmung_01_oMIBCAN: start 0, 8 bit, little-endian, i-signal-type=PRIMITIVE, init-value=254, base-type=uint8, compu-method=CM_DI_KL_58xd, data-constr=DC_DI_KL_58xd, transfer-property=TRIGGERED-ON-CHANGE-WITHOUT-REPETITION, to ABT_1_MIB_ab_Gen3(timeout 2 s)  # Klemme 58xd Display- und Funktionsbeleuchtung Mit der Klemme 58xd wird die Helligkeit der Display- und der Funktionsbeleuchtungen der Schalter gesteuert. Im Detail beschrieben im 'Funktionslastenheft Dimmung MQB'.
          signal DI_KL_58xs_oDimmung_01_oMIBCAN: start 8, 7 bit, little-endian, i-signal-type=PRIMITIVE, init-value=126, base-type=uint8, compu-method=CM_DI_KL_58xs, data-constr=DC_DI_KL_58xs, unit=Unit_PerCent, transfer-property=TRIGGERED-ON-CHANGE-WITHOUT-REPETITION, to ABT_1_MIB_ab_Gen3(timeout 2 s)  # Suchbeleuchtung Schalter EIN-AUS-Schaltalgorithmus der allgemeinen Schaltersuchbeleuchtung. Im Detail beschrieben im 'Funktionslastenheft Dimmung MQB'.
          signal DI_Display_Nachtdesign_oDimmung_01_oMIBCAN: start 15, 1 bit, little-endian, i-signal-type=PRIMITIVE, init-value=0, base-type=boolean, compu-method=CM_DI_Display_Nachtdesign, data-constr=DC_DI_Display_Nachtdesign, transfer-property=TRIGGERED-ON-CHANGE-WITHOUT-REPETITION, to ABT_1_MIB_ab_Gen3(timeout 2 s)  # Für Displays sind oft automatische Umschaltungen von Tag-/Nachtdesign vorgesehen. Es gibt jedoch Zustände, an denen auch tagsüber das Abblendlicht eingeschaltet ist. z.B. Dauerfahrlicht, Geschwindigkeitsabhängiges 'Licht-An-Bei-Autobahn', 'Regenlicht',
          signal DI_KL_58xt_oDimmung_01_oMIBCAN: start 16, 7 bit, little-endian, i-signal-type=PRIMITIVE, init-value=126, base-type=uint8, compu-method=CM_DI_KL_58xt, data-constr=DC_DI_KL_58xt, unit=Unit_PerCent, transfer-property=TRIGGERED-ON-CHANGE-WITHOUT-REPETITION, to ABT_1_MIB_ab_Gen3(timeout 2 s)  # Timergesteuerte Suchbeleuchtung Der EIN-AUS-Schaltalgorithmus für die vor- und nachlaufende Schaltersuchbeleuchtungen beim Ein- & Aussteigen; z.B.: Start/Stop-Taster. Im Detail beschrieben im 'Funktionslastenheft Dimmung MQB'.
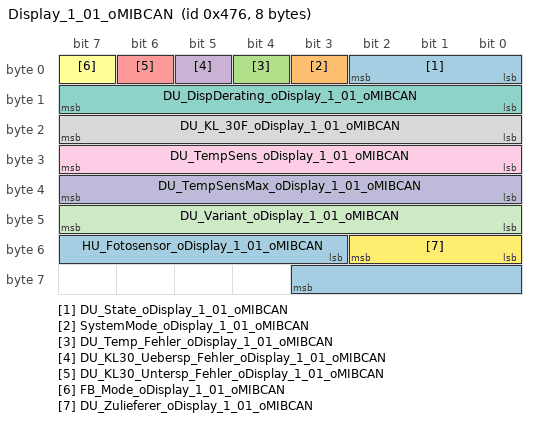
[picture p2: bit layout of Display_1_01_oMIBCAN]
      frame Display_1_01_oMIBCAN: id 0x476, from ABT_1_MIB_ab_Gen3, frame-length=8, can-addressing-mode=STANDARD
        pdu Display_1_01_oMIBCAN: length=8, minimum-delay=0.04, transmission-mode-false-timing={cyclic-timing={time-offset=0, time-period=1}, event-controlled-timing={number-of-repetitions=0, repetition-period=0}}, transmission-mode-true-timing={cyclic-timing={time-offset=0, time-period=1}, event-controlled-timing={number-of-repetitions=0, repetition-period=0}}, unused-bit-pattern=0
          signal DU_State_oDisplay_1_01_oMIBCAN: start 0, 3 bit, little-endian, i-signal-type=PRIMITIVE, init-value=0, base-type=uint8, compu-method=CM_DU_State, data-constr=DC_DU_State, transfer-property=TRIGGERED-ON-CHANGE-WITHOUT-REPETITION  # Power state des Displays.
          signal SystemMode_oDisplay_1_01_oMIBCAN: start 3, 1 bit, little-endian, i-signal-type=PRIMITIVE, init-value=0, base-type=boolean, compu-method=CM_SystemMode, data-constr=DC_SystemMode, transfer-property=TRIGGERED-ON-CHANGE-WITHOUT-REPETITION
          signal DU_Temp_Fehler_oDisplay_1_01_oMIBCAN: start 4, 1 bit, little-endian, i-signal-type=PRIMITIVE, init-value=0, base-type=boolean, compu-method=CM_DU_Temp_Fehler, data-constr=DC_DU_Temp_Fehler, transfer-property=TRIGGERED-ON-CHANGE-WITHOUT-REPETITION  # Die Display Unit hat einen Temperaturfehler erkannt.
          signal DU_KL30_Uebersp_Fehler_oDisplay_1_01_oMIBCAN: start 5, 1 bit, little-endian, i-signal-type=PRIMITIVE, init-value=0, base-type=boolean, compu-method=CM_DU_KL30_Uebersp_Fehler, data-constr=DC_DU_KL30_Uebersp_Fehler, transfer-property=TRIGGERED-ON-CHANGE-WITHOUT-REPETITION  # Display Unit Erkannter Überspannungsfehler
          signal DU_KL30_Untersp_Fehler_oDisplay_1_01_oMIBCAN: start 6, 1 bit, little-endian, i-signal-type=PRIMITIVE, init-value=0, base-type=boolean, compu-method=CM_DU_KL30_Untersp_Fehler, data-constr=DC_DU_KL30_Untersp_Fehler, transfer-property=TRIGGERED-ON-CHANGE-WITHOUT-REPETITION  # Display Unit Erkannter Unterspannungsfehler
          signal FB_Mode_oDisplay_1_01_oMIBCAN: start 7, 1 bit, little-endian, i-signal-type=PRIMITIVE, init-value=0, base-type=boolean, compu-method=CM_FB_Mode, data-constr=DC_FB_Mode, transfer-property=TRIGGERED-ON-CHANGE-WITHOUT-REPETITION  # Steuergerät ist im Fernbedienmodus
          signal DU_DispDerating_oDisplay_1_01_oMIBCAN: start 8, 8 bit, little-endian, i-signal-type=PRIMITIVE, init-value=254, base-type=uint8, compu-method=CM_DU_DispDerating, data-constr=DC_DU_DispDerating, unit=Unit_PerCent, transfer-property=PENDING  # Begrenzung der Verlustleistung in Abhaengigkeit der Temperatur
          signal DU_KL_30F_oDisplay_1_01_oMIBCAN: start 16, 8 bit, little-endian, i-signal-type=PRIMITIVE, init-value=254, base-type=uint8, compu-method=CM_DU_KL_30F, data-constr=DC_DU_KL_30F, unit=Unit_Volt, transfer-property=PENDING  # Gemessene Versorgungsspannung des Displays.
          signal DU_TempSens_oDisplay_1_01_oMIBCAN: start 24, 8 bit, little-endian, i-signal-type=PRIMITIVE, init-value=254, base-type=uint8, compu-method=CM_DU_TempSens, data-constr=DC_DU_TempSens, unit=Unit_DegreCelsi, transfer-property=PENDING  # Display Unit aktueller Temperaturwert
          signal DU_TempSensMax_oDisplay_1_01_oMIBCAN: start 32, 8 bit, little-endian, i-signal-type=PRIMITIVE, init-value=254, base-type=uint8, compu-method=CM_DU_TempSensMax, data-constr=DC_DU_TempSensMax, unit=Unit_DegreCelsi, transfer-property=PENDING  # Gespeicherte maximale Sensortemperatur . Wert bleibt über Ruhestrom erhalten.
          signal DU_Variant_oDisplay_1_01_oMIBCAN: start 40, 8 bit, little-endian, i-signal-type=PRIMITIVE, init-value=254, base-type=uint8, compu-method=CM_DU_Variant, data-constr=DC_DU_Variant, transfer-property=PENDING  # Variante der Display Unit siehe MIB_ABT_EEPROM-AdjustDeviceNr_V01E_20100715_woj.xls
          signal DU_Zulieferer_oDisplay_1_01_oMIBCAN: start 48, 3 bit, little-endian, i-signal-type=PRIMITIVE, init-value=0, base-type=uint8, compu-method=CM_DU_Zulieferer, data-constr=DC_DU_Zulieferer, transfer-property=PENDING  # Zulieferer des Displays. Je nach eingesetztem Display müssen für das HMI unterschiedliche Grafiken verwendet werden damit die angezeigten Bilder immer identisch aussehen.
          signal HU_Fotosensor_oDisplay_1_01_oMIBCAN: start 51, 9 bit, little-endian, i-signal-type=PRIMITIVE, init-value=510, base-type=uint16, compu-method=CM_HU_Fotosensor, data-constr=DC_HU_Fotosensor, unit=Unit_PerCent, transfer-property=PENDING  # Messwert Fotosensor der Headunit (PCM bzw. CDR) logarithmisch verzerrt (siehe Funktionsbeschreibung Nachtdesign - entsprechend Audi-Spec) PCM/CDR_Signal
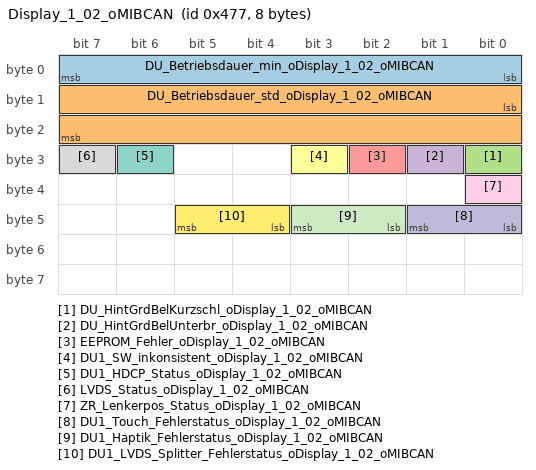
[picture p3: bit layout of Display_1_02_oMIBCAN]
      frame Display_1_02_oMIBCAN: id 0x477, from ABT_1_MIB_ab_Gen3, frame-length=8, can-addressing-mode=STANDARD
        pdu Display_1_02_oMIBCAN: length=8, minimum-delay=0.04, transmission-mode-false-timing={cyclic-timing={time-offset=0, time-period=1}, event-controlled-timing={number-of-repetitions=0, repetition-period=0}}, transmission-mode-true-timing={cyclic-timing={time-offset=0, time-period=1}, event-controlled-timing={number-of-repetitions=0, repetition-period=0}}, unused-bit-pattern=0
          signal DU_Betriebsdauer_min_oDisplay_1_02_oMIBCAN: start 0, 8 bit, little-endian, i-signal-type=PRIMITIVE, init-value=254, base-type=uint8, compu-method=CM_DU_Betriebsdauer_min, data-constr=DC_DU_Betriebsdauer_min, unit=Unit_Minut, transfer-property=PENDING  # Display Betriebsdauer Minutenanteil
          signal DU_Betriebsdauer_std_oDisplay_1_02_oMIBCAN: start 8, 16 bit, little-endian, i-signal-type=PRIMITIVE, init-value=65534, base-type=uint16, compu-method=CM_DU_Betriebsdauer_std, data-constr=DC_DU_Betriebsdauer_std, unit=Unit_Hours, transfer-property=PENDING  # Display Betriebsdauer Stundenanteil
          signal DU_HintGrdBelKurzschl_oDisplay_1_02_oMIBCAN: start 24, 1 bit, little-endian, i-signal-type=PRIMITIVE, init-value=0, base-type=boolean, compu-method=CM_DU_HintGrdBelKurzschl, data-constr=DC_DU_HintGrdBelKurzschl, transfer-property=TRIGGERED-ON-CHANGE-WITHOUT-REPETITION  # Hintergrundbeleuchtung hat einen Kurzschluß.
          signal DU_HintGrdBelUnterbr_oDisplay_1_02_oMIBCAN: start 25, 1 bit, little-endian, i-signal-type=PRIMITIVE, init-value=0, base-type=boolean, compu-method=CM_DU_HintGrdBelUnterbr, data-constr=DC_DU_HintGrdBelUnterbr, transfer-property=TRIGGERED-ON-CHANGE-WITHOUT-REPETITION  # Ueber Strommessungen, mindestens ein LED Strang unterbrochen.
          signal EEPROM_Fehler_oDisplay_1_02_oMIBCAN: start 26, 1 bit, little-endian, i-signal-type=PRIMITIVE, init-value=0, base-type=boolean, compu-method=CM_EEPROM_Fehler, data-constr=DC_EEPROM_Fehler, transfer-property=TRIGGERED-ON-CHANGE-WITHOUT-REPETITION  # EEPROM Defekt erkannt.
          signal DU1_SW_inkonsistent_oDisplay_1_02_oMIBCAN: start 27, 1 bit, little-endian, i-signal-type=PRIMITIVE, init-value=0, base-type=boolean, compu-method=CM_DU1_SW_inkonsistent, data-constr=DC_DU1_SW_inkonsistent, transfer-property=PENDING  # SW_inkonsistent= 1 SW Status ist inkonsistent - Fehler SW_inkonsistent = 0 kien Fehler - SW ist konsistent
          signal DU1_HDCP_Status_oDisplay_1_02_oMIBCAN: start 30, 1 bit, little-endian, i-signal-type=PRIMITIVE, init-value=0, base-type=boolean, compu-method=CM_DU1_HDCP_Status, data-constr=DC_DU1_HDCP_Status, transfer-property=TRIGGERED-ON-CHANGE-WITHOUT-REPETITION  # Aktueller HDCP Status
          signal LVDS_Status_oDisplay_1_02_oMIBCAN: start 31, 1 bit, little-endian, i-signal-type=PRIMITIVE, init-value=0, base-type=boolean, compu-method=CM_LVDS_Status, data-constr=DC_LVDS_Status, transfer-property=TRIGGERED-ON-CHANGE-WITHOUT-REPETITION  # LVDS_Lock= 1 Statussignal in der DU Ein valides Videosignal zum Anzeigen liegt an LVDS_Unlocked = 0 kein Videosignal liegt an
          signal ZR_Lenkerpos_Status_oDisplay_1_02_oMIBCAN: start 32, 1 bit, little-endian, i-signal-type=PRIMITIVE, init-value=0, base-type=boolean, compu-method=CM_ZR_Lenkerpos_Status, data-constr=DC_ZR_Lenkerpos_Status, transfer-property=PENDING  # Im ABT gespeicherte Lenkradposition. Die Lenkradposition wird wie im Signal ZR_Lenkerposition gesendet nach einer Qualifizierungszeit von voraussichtlich 10 Botschaften übernommen.
          signal DU1_Touch_Fehlerstatus_oDisplay_1_02_oMIBCAN: start 40, 2 bit, little-endian, i-signal-type=PRIMITIVE, init-value=0, base-type=uint8, compu-method=CM_DU1_Touch_Fehlerstatus, data-constr=DC_DU1_Touch_Fehlerstatus, transfer-property=PENDING  # Touch_Fehlerstatus = 0 kein Fehler erkannt Touch_Fehlerstatus = 1 SW Fehler erkannt Touch_Fehlerstatus = 2 HW Fehler erkannt
          signal DU1_Haptik_Fehlerstatus_oDisplay_1_02_oMIBCAN: start 42, 2 bit, little-endian, i-signal-type=PRIMITIVE, init-value=0, base-type=uint8, compu-method=CM_DU1_Haptik_Fehlerstatus, data-constr=DC_DU1_Haptik_Fehlerstatus, transfer-property=PENDING  # Haptik_Fehlerstatus = 0 kein Fehler erkannt Haptik_Fehlerstatus = 1 SW Fehler erkannt Haptik_Fehlerstatus = 2 HW Fehler erkannt
          signal DU1_LVDS_Splitter_Fehlerstatus_oDisplay_1_02_oMIBCAN: start 44, 2 bit, little-endian, i-signal-type=PRIMITIVE, init-value=0, base-type=uint8, compu-method=CM_DU1_LVDS_Splitter_Fehlerstatus, data-constr=DC_DU1_LVDS_Splitter_Fehlerstatus, transfer-property=PENDING  # LVDS_Splitter_Fehlerstatus = 0 kein Fehler erkannt LVDS_Splitter_Fehlerstatus = 1 SW Fehler erkannt LVDS_Splitter_Fehlerstatus = 2 HW Fehler erkannt
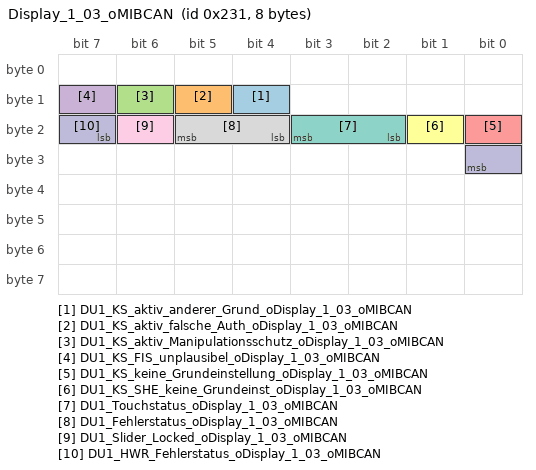
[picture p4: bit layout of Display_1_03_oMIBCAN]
      frame Display_1_03_oMIBCAN: id 0x231, from ABT_1_MIB_ab_Gen3, frame-length=8, can-addressing-mode=STANDARD
        pdu Display_1_03_oMIBCAN: length=8, minimum-delay=0.02, transmission-mode-false-timing={cyclic-timing={time-offset=0, time-period=0.2}, event-controlled-timing={number-of-repetitions=0, repetition-period=0}}, transmission-mode-true-timing={cyclic-timing={time-offset=0, time-period=0.2}, event-controlled-timing={number-of-repetitions=0, repetition-period=0}}, unused-bit-pattern=0
          signal DU1_KS_aktiv_anderer_Grund_oDisplay_1_03_oMIBCAN: start 12, 1 bit, little-endian, i-signal-type=PRIMITIVE, init-value=0, base-type=boolean, compu-method=CM_DU1_KS_aktiv_anderer_Grund, data-constr=DC_DU1_KS_aktiv_anderer_Grund, transfer-property=TRIGGERED-ON-CHANGE-WITHOUT-REPETITION  # DTC Display Unit Komponentenschutz - Aktiv (anderer Grund)
          signal DU1_KS_aktiv_falsche_Auth_oDisplay_1_03_oMIBCAN: start 13, 1 bit, little-endian, i-signal-type=PRIMITIVE, init-value=0, base-type=boolean, compu-method=CM_DU1_KS_aktiv_falsche_Auth, data-constr=DC_DU1_KS_aktiv_falsche_Auth, transfer-property=TRIGGERED-ON-CHANGE-WITHOUT-REPETITION  # DTC Display Unit Komponentenschutz - Aktiv (Falschauthentifikation)
          signal DU1_KS_aktiv_Manipulationsschutz_oDisplay_1_03_oMIBCAN: start 14, 1 bit, little-endian, i-signal-type=PRIMITIVE, init-value=0, base-type=boolean, compu-method=CM_DU1_KS_aktiv_Manipulationsschutz, data-constr=DC_DU1_KS_aktiv_Manipulationsschutz, transfer-property=TRIGGERED-ON-CHANGE-WITHOUT-REPETITION  # DTC Display Unit Komponentenschutz - Aktiv (Manipulationsschutz)
          signal DU1_KS_FIS_unplausibel_oDisplay_1_03_oMIBCAN: start 15, 1 bit, little-endian, i-signal-type=PRIMITIVE, init-value=0, base-type=boolean, compu-method=CM_DU1_KS_FIS_unplausibel, data-constr=DC_DU1_KS_FIS_unplausibel, transfer-property=TRIGGERED-ON-CHANGE-WITHOUT-REPETITION  # DTC Display Unit Komponentenschutz - FAZIT-Identifikation unplausibel
          signal DU1_KS_keine_Grundeinstellung_oDisplay_1_03_oMIBCAN: start 16, 1 bit, little-endian, i-signal-type=PRIMITIVE, init-value=0, base-type=boolean, compu-method=CM_DU1_KS_keine_Grundeinstellung, data-constr=DC_DU1_KS_keine_Grundeinstellung, transfer-property=TRIGGERED-ON-CHANGE-WITHOUT-REPETITION  # DTC Display Unit Komponentenschutz - keine oder falsche Grundeinstellung
          signal DU1_KS_SHE_keine_Grundeinst_oDisplay_1_03_oMIBCAN: start 17, 1 bit, little-endian, i-signal-type=PRIMITIVE, init-value=0, base-type=boolean, compu-method=CM_DU1_KS_SHE_keine_Grundeinst, data-constr=DC_DU1_KS_SHE_keine_Grundeinst, transfer-property=TRIGGERED-ON-CHANGE-WITHOUT-REPETITION  # DTC Display Unit Komponentenschutz - SHE-Schlüssel keine oder falsche Grundeinstellung
          signal DU1_Touchstatus_oDisplay_1_03_oMIBCAN: start 18, 2 bit, little-endian, i-signal-type=PRIMITIVE, init-value=0, base-type=uint8, compu-method=CM_DU1_Touchstatus, data-constr=DC_DU1_Touchstatus, transfer-property=TRIGGERED-ON-CHANGE-WITHOUT-REPETITION  # Status if display unit (DU) is touched or not.
          signal DU1_Fehlerstatus_oDisplay_1_03_oMIBCAN: start 20, 2 bit, little-endian, i-signal-type=PRIMITIVE, init-value=0, base-type=uint8, compu-method=CM_DU1_Fehlerstatus, data-constr=DC_DU1_Fehlerstatus, transfer-property=TRIGGERED-ON-CHANGE-WITHOUT-REPETITION  # Indicates the error status of the ABT.
          signal DU1_Slider_Locked_oDisplay_1_03_oMIBCAN: start 22, 1 bit, little-endian, i-signal-type=PRIMITIVE, init-value=0, base-type=boolean, compu-method=CM_DU1_Slider_Locked, data-constr=DC_DU1_Slider_Locked, transfer-property=TRIGGERED-ON-CHANGE-WITHOUT-REPETITION  # Gives Status from ABT slider if slider is locked or unlocked. Signal mapped according to the hard wiring between ABT and DiETa.
          signal DU1_HWR_Fehlerstatus_oDisplay_1_03_oMIBCAN: start 23, 2 bit, little-endian, i-signal-type=PRIMITIVE, init-value=0, base-type=uint8, compu-method=CM_DU1_HWR_Fehlerstatus, data-constr=DC_DU1_HWR_Fehlerstatus, transfer-property=PENDING  # HWR_Fehlerstatus = 0 kein Fehler erkannt HWR_Fehlerstatus = 1 SW Fehler erkannt HWR_Fehlerstatus = 2 HW Fehler erkannt
      frame HID_ABT_1_ZR_Req_oMIBCAN: id 0x17F8F173, from ABT_1_MIB_ab_Gen3, frame-length=8, can-addressing-mode=EXTENDED
        n pdu HID_ABT_1_ZR_Req_Tp_oMIBCAN: length=8
      frame HID_ABT_1_ZR_Resp_oMIBCAN: id 0x17FA73F1, to ABT_1_MIB_ab_Gen3, frame-length=8, can-addressing-mode=EXTENDED
        n pdu HID_ABT_1_ZR_Resp_Tp_oMIBCAN: length=8
      frame HID_ZR_ABT_1_Req_oMIBCAN: id 0x17F873F1, to ABT_1_MIB_ab_Gen3, frame-length=8, can-addressing-mode=EXTENDED
        n pdu HID_ZR_ABT_1_Req_Tp_oMIBCAN: length=8
      frame HID_ZR_ABT_1_Resp_oMIBCAN: id 0x17FAF173, from ABT_1_MIB_ab_Gen3, frame-length=8, can-addressing-mode=EXTENDED
        n pdu HID_ZR_ABT_1_Resp_Tp_oMIBCAN: length=8
      frame Klemmen_Status_01_oMIBCAN: id 0x3C0, to ABT_1_MIB_ab_Gen3, frame-length=4, can-addressing-mode=STANDARD  # MQB
        pdu Klemmen_Status_01_oMIBCAN: length=4, minimum-delay=0, transmission-mode-false-timing=event-controlled-timing={number-of-repetitions=0, repetition-period=0}, transmission-mode-true-timing=event-controlled-timing={number-of-repetitions=0, repetition-period=0}, unused-bit-pattern=0
          signal Klemmen_Status_01_CRC_oKlemmen_Status_01_oMIBCAN: start 0, 8 bit, little-endian, i-signal-type=PRIMITIVE, init-value=0, base-type=uint8, compu-method=CM_Klemmen_Status_01_CRC, data-constr=DC_Klemmen_Status_01_CRC, transfer-property=TRIGGERED-WITHOUT-REPETITION, to ABT_1_MIB_ab_Gen3  # Für MLB: 'Berechnung siehe Lastenheft 'Kommunikationsabsicherung für FlexRay und CAN'' Ab MQB und MLBevo: 'Berechnung siehe Lastenheft 'End-to-End Kommunikationsabsicherung'' Endwerte siehe Begleitdokument 'S-PDU Kennungsfolgen'
          signal Klemmen_Status_01_BZ_oKlemmen_Status_01_oMIBCAN: start 8, 4 bit, little-endian, i-signal-type=PRIMITIVE, init-value=0, base-type=uint8, compu-method=CM_Klemmen_Status_01_BZ, data-constr=DC_Klemmen_Status_01_BZ, transfer-property=TRIGGERED-WITHOUT-REPETITION, to ABT_1_MIB_ab_Gen3  # 4bit Botschaftszaehler; wird in jeder Sendebotschaft inkrementiert
          signal RSt_Fahrerhinweise_oKlemmen_Status_01_oMIBCAN: start 12, 4 bit, little-endian, i-signal-type=PRIMITIVE, init-value=0, base-type=uint8, compu-method=CM_RSt_Fahrerhinweise, data-constr=DC_RSt_Fahrerhinweise, transfer-property=PENDING, to ABT_1_MIB_ab_Gen3  # Über das Signal fordert das BCM Fahrerhinweise im Kombi für die Funktion RemoteStart an.
          signal ZAS_Kl_S_oKlemmen_Status_01_oMIBCAN: start 16, 1 bit, little-endian, i-signal-type=PRIMITIVE, init-value=0, base-type=boolean, compu-method=CM_ZAS_Kl_S, data-constr=DC_ZAS_Kl_S, transfer-property=PENDING, to ABT_1_MIB_ab_Gen3  # Klemme S: S-Kontakt (Schluessel steckt)
          signal ZAS_Kl_15_oKlemmen_Status_01_oMIBCAN: start 17, 1 bit, little-endian, i-signal-type=PRIMITIVE, init-value=0, base-type=boolean, compu-method=CM_ZAS_Kl_15, data-constr=DC_ZAS_Kl_15, transfer-property=PENDING, to ABT_1_MIB_ab_Gen3  # Klemme 15: Zuendung (SW-Kl.15)
          signal ZAS_Kl_X_oKlemmen_Status_01_oMIBCAN: start 18, 1 bit, little-endian, i-signal-type=PRIMITIVE, init-value=0, base-type=boolean, compu-method=CM_ZAS_Kl_X, data-constr=DC_ZAS_Kl_X, transfer-property=PENDING, to ABT_1_MIB_ab_Gen3  # Klemme 75
          signal ZAS_Kl_50_Startanforderung_oKlemmen_Status_01_oMIBCAN: start 19, 1 bit, little-endian, i-signal-type=PRIMITIVE, init-value=0, base-type=boolean, compu-method=CM_ZAS_Kl_50_Startanforderung, data-constr=DC_ZAS_Kl_50_Startanforderung, transfer-property=PENDING, to ABT_1_MIB_ab_Gen3  # Klemme 50: Startwunsch Fahrer
          signal BCM_Remotestart_Betrieb_oKlemmen_Status_01_oMIBCAN: start 20, 1 bit, little-endian, i-signal-type=PRIMITIVE, init-value=0, base-type=boolean, compu-method=CM_BCM_Remotestart_Betrieb, data-constr=DC_BCM_Remotestart_Betrieb, transfer-property=PENDING, variation-point=post-build-variant-condition{matching-criterion=Communication, value=0}, to ABT_1_MIB_ab_Gen3  # Zeigt den Status des RemoteStarts an, d.h. KL15_RSt ist aktiviert und der Motorlauf ist im RSt-Betrieb aktiv.
          signal ZAS_Kl_Infotainment_oKlemmen_Status_01_oMIBCAN: start 21, 1 bit, little-endian, i-signal-type=PRIMITIVE, init-value=0, base-type=boolean, compu-method=CM_ZAS_Kl_Infotainment, data-constr=DC_ZAS_Kl_Infotainment, transfer-property=PENDING, to ABT_1_MIB_ab_Gen3  # Separate Klemmeninformation für das Infotainment. Signal entspricht im wesentlichen einer Klemme S Information, kann aber über einen Vor - bzw. Nachlauf zu Klemme S verfügen. Ein konkreter Anwendungsfall für einen Nachlauf ist die Abschaltung der Klemme
          signal BCM_Remotestart_KL15_Anf_oKlemmen_Status_01_oMIBCAN: start 22, 1 bit, little-endian, i-signal-type=PRIMITIVE, init-value=0, base-type=boolean, compu-method=CM_BCM_Remotestart_KL15_Anf, data-constr=DC_BCM_Remotestart_KL15_Anf, transfer-property=PENDING, variation-point=post-build-variant-condition{matching-criterion=Communication, value=0}, to ABT_1_MIB_ab_Gen3  # Zeigt den Status der Aktivierung der KL15_RST durch das BCM an.
          signal BCM_Remotestart_MO_Start_oKlemmen_Status_01_oMIBCAN: start 23, 1 bit, little-endian, i-signal-type=PRIMITIVE, init-value=0, base-type=boolean, compu-method=CM_BCM_Remotestart_MO_Start, data-constr=DC_BCM_Remotestart_MO_Start, transfer-property=PENDING, variation-point=post-build-variant-condition{matching-criterion=Communication, value=0}, to ABT_1_MIB_ab_Gen3  # Nachdem das BCM die Remotestart MSG Freigabe sicher erkannt hat, fordert das BCM wiederum über dieses Signal vom MSG einen Motorstart durchzuführen.
          signal KST_Warn_P1_ZST_def_oKlemmen_Status_01_oMIBCAN: start 24, 1 bit, little-endian, i-signal-type=PRIMITIVE, init-value=0, base-type=boolean, compu-method=CM_KST_Warn_P1_ZST_def, data-constr=DC_KST_Warn_P1_ZST_def, transfer-property=PENDING, to ABT_1_MIB_ab_Gen3  # Kombi Prio Warnung Klemmensteuerung Zündschloß defekt, Service aufsuchen!
          signal KST_Warn_P2_ZST_def_oKlemmen_Status_01_oMIBCAN: start 25, 1 bit, little-endian, i-signal-type=PRIMITIVE, init-value=0, base-type=boolean, compu-method=CM_KST_Warn_P2_ZST_def, data-constr=DC_KST_Warn_P2_ZST_def, transfer-property=PENDING, to ABT_1_MIB_ab_Gen3  # Kombi Prio Warnung Klemmensteuerung Zündschloß defekt!
          signal KST_Fahrerhinweis_1_oKlemmen_Status_01_oMIBCAN: start 26, 1 bit, little-endian, i-signal-type=PRIMITIVE, init-value=0, base-type=boolean, compu-method=CM_KST_Fahrerhinweis_1, data-constr=DC_KST_Fahrerhinweis_1, transfer-property=PENDING, to ABT_1_MIB_ab_Gen3  # Signalisierung Fahrerhinweis 1 der Klemmensteuerung an das Kombi
          signal KST_Fahrerhinweis_2_oKlemmen_Status_01_oMIBCAN: start 27, 1 bit, little-endian, i-signal-type=PRIMITIVE, init-value=0, base-type=boolean, compu-method=CM_KST_Fahrerhinweis_2, data-constr=DC_KST_Fahrerhinweis_2, transfer-property=PENDING, to ABT_1_MIB_ab_Gen3  # Signalisierung Fahrerhinweis 2 der Klemmensteuerung an das Kombi
          signal BCM_Ausparken_Betrieb_oKlemmen_Status_01_oMIBCAN: start 28, 1 bit, little-endian, i-signal-type=PRIMITIVE, init-value=0, base-type=boolean, compu-method=CM_BCM_Ausparken_Betrieb, data-constr=DC_BCM_Ausparken_Betrieb, transfer-property=PENDING, to ABT_1_MIB_ab_Gen3  # Anforderung zur erneuten Lampenaufprüfung und Anzeige von Warnhinweisen nach einem pilotierten Ausparkvorgang (Trigger: fallende Flanke)
          signal KST_Fahrerhinweis_4_oKlemmen_Status_01_oMIBCAN: start 29, 1 bit, little-endian, i-signal-type=PRIMITIVE, init-value=0, base-type=boolean, compu-method=CM_KST_Fahrerhinweis_4, data-constr=DC_KST_Fahrerhinweis_4, transfer-property=PENDING, to ABT_1_MIB_ab_Gen3  # Signalisierung Fahrerhinweis 4 der Klemmensteuerung an das Kombi
          signal KST_Fahrerhinweis_5_oKlemmen_Status_01_oMIBCAN: start 30, 1 bit, little-endian, i-signal-type=PRIMITIVE, init-value=0, base-type=boolean, compu-method=CM_KST_Fahrerhinweis_5, data-constr=DC_KST_Fahrerhinweis_5, transfer-property=PENDING, to ABT_1_MIB_ab_Gen3  # Anzeigesignal für RemoteStart
          signal KST_Fahrerhinweis_6_oKlemmen_Status_01_oMIBCAN: start 31, 1 bit, little-endian, i-signal-type=PRIMITIVE, init-value=0, base-type=boolean, compu-method=CM_KST_Fahrerhinweis_6, data-constr=DC_KST_Fahrerhinweis_6, transfer-property=PENDING, to ABT_1_MIB_ab_Gen3  # Signal aktiviert die Kombi-Anzeigeinstrumente (Drehzahl, Tankinhalt, Kühlmitteltemperatur) während aktiviertem RemoteStart-Betrieb
          mapping SG_Klemmen_Status_01: i-signal-group=ISignal/SG_Klemmen_Status_01_oKlemmen_Status_01_oMIBCAN, transfer-property=PENDING
          signal Klemmen_Status_01_0x14_0x01_oKlemmen_Status_01_oMIBCAN: start 20, 1 bit, little-endian, i-signal-type=PRIMITIVE, base-type=boolean, variation-point=post-build-variant-condition{matching-criterion=Communication, value=1}, to ABT_1_MIB_ab_Gen3
          signal Klemmen_Status_01_0x16_0x02_oKlemmen_Status_01_oMIBCAN: start 22, 2 bit, little-endian, i-signal-type=PRIMITIVE, base-type=uint8, variation-point=post-build-variant-condition{matching-criterion=Communication, value=1}, to ABT_1_MIB_ab_Gen3
      frame KS_SSN_ABT_1_Req_oMIBCAN: id 0x17FC600E, to ABT_1_MIB_ab_Gen3, frame-length=8, can-addressing-mode=EXTENDED
        n pdu KS_SSN_ABT_1_Req_Tp_oMIBCAN: length=8
      frame KS_SSN_ABT_1_Resp_oMIBCAN: id 0x17FE600E, from ABT_1_MIB_ab_Gen3, frame-length=8, can-addressing-mode=EXTENDED
        n pdu KS_SSN_ABT_1_Resp_Tp_oMIBCAN: length=8
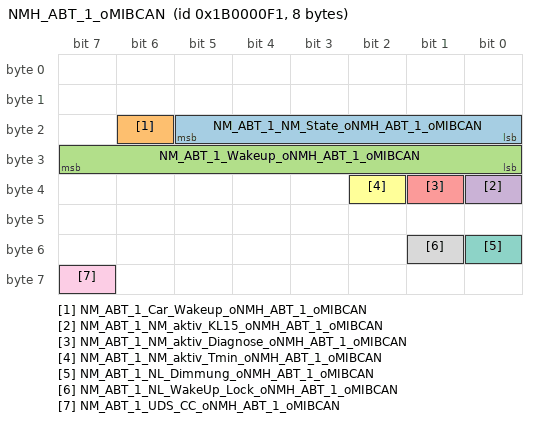
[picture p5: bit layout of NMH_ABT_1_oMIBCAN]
      frame NMH_ABT_1_oMIBCAN: id 0x1B0000F1, from ABT_1_MIB_ab_Gen3, frame-length=8, can-addressing-mode=EXTENDED
        nm pdu NMH_ABT_1_oMIBCAN: length=8, unused-bit-pattern=0
          signal NM_ABT_1_NM_State_oNMH_ABT_1_oMIBCAN: start 16, 6 bit, little-endian, i-signal-type=PRIMITIVE, init-value=0, base-type=uint8, compu-method=CM_NM_ABT_1_NM_State, data-constr=DC_NM_ABT_1_NM_State, transfer-property=PENDING  # 1 = Zustand Repeat Message (<-- Bus-Sleep Mode) 2 = Zustand Repeat Message (<-- Prepare Bus-Sleep Mode) 4 = Zustand Normal Operation (<-- Repeat Message) 8 = Zustand Normal Operation (<-- Ready Sleep)
          signal NM_ABT_1_Car_Wakeup_oNMH_ABT_1_oMIBCAN: start 22, 1 bit, little-endian, i-signal-type=PRIMITIVE, init-value=0, base-type=boolean, compu-method=CM_NM_ABT_1_Car_Wakeup, data-constr=DC_NM_ABT_1_Car_Wakeup, transfer-property=PENDING  # Car Wakeup (Gateway wertet aus)
          signal NM_ABT_1_Wakeup_oNMH_ABT_1_oMIBCAN: start 24, 8 bit, little-endian, i-signal-type=PRIMITIVE, init-value=0, base-type=uint8, compu-method=CM_NM_ABT_1_Wakeup, data-constr=DC_NM_ABT_1_Wakeup, transfer-property=PENDING  # enthält die Weckursache; stehen mehrere Weckursachen parallel an, dann muss der kleinste Wert übertragen werden
          signal NM_ABT_1_NM_aktiv_KL15_oNMH_ABT_1_oMIBCAN: start 32, 1 bit, little-endian, i-signal-type=PRIMITIVE, init-value=0, base-type=boolean, compu-method=CM_NM_ABT_1_NM_aktiv_KL15, data-constr=DC_NM_ABT_1_NM_aktiv_KL15, transfer-property=PENDING  # Steuergerät hat KL15-EIN erkannt
          signal NM_ABT_1_NM_aktiv_Diagnose_oNMH_ABT_1_oMIBCAN: start 33, 1 bit, little-endian, i-signal-type=PRIMITIVE, init-value=0, base-type=boolean, compu-method=CM_NM_ABT_1_NM_aktiv_Diagnose, data-constr=DC_NM_ABT_1_NM_aktiv_Diagnose, transfer-property=PENDING  # Diagnose befindet sich nach VW80124 in einer NonDefaultDiagnostic-Session, z.B. ExtendedDiagnostic-Session
          signal NM_ABT_1_NM_aktiv_Tmin_oNMH_ABT_1_oMIBCAN: start 34, 1 bit, little-endian, i-signal-type=PRIMITIVE, init-value=0, base-type=boolean, compu-method=CM_NM_ABT_1_NM_aktiv_Tmin, data-constr=DC_NM_ABT_1_NM_aktiv_Tmin, transfer-property=PENDING  # Mindestaktivzeit ist noch nicht abgelaufen (bei jedem Weckereignis wird die Mindestaktivzeit neu gestartet)
          signal NM_ABT_1_NL_Dimmung_oNMH_ABT_1_oMIBCAN: start 48, 1 bit, little-endian, i-signal-type=PRIMITIVE, init-value=0, base-type=boolean, compu-method=CM_NM_ABT_1_NL_Dimmung, data-constr=DC_NM_ABT_1_NL_Dimmung, transfer-property=PENDING  # lokale / interne Aktivität vor WakeUp: Dimmung aktiv
          signal NM_ABT_1_NL_WakeUp_Lock_oNMH_ABT_1_oMIBCAN: start 49, 1 bit, little-endian, i-signal-type=PRIMITIVE, init-value=0, base-type=boolean, compu-method=CM_NM_ABT_1_NL_WakeUp_Lock, data-constr=DC_NM_ABT_1_NL_WakeUp_Lock, transfer-property=PENDING  # lokale / interne Aktivität vor WakeUp: HID ist aufgrund des Transportmodus, Q_critical oder WU_lock gesperrt.
          signal NM_ABT_1_UDS_CC_oNMH_ABT_1_oMIBCAN: start 63, 1 bit, little-endian, i-signal-type=PRIMITIVE, init-value=0, base-type=boolean, compu-method=CM_NM_ABT_1_UDS_CC, data-constr=DC_NM_ABT_1_UDS_CC, transfer-property=PENDING  # Funktionseinschränkung aufgrund aktivem UDS-Communication Control; siehe VW80124
      frame NMH_DU_1_oMIBCAN: id 0x1B0000F2, to ABT_1_MIB_ab_Gen3, frame-length=8, can-addressing-mode=EXTENDED
        nm pdu NMH_DU_1_oMIBCAN: length=8, unused-bit-pattern=0
      frame NMH_DU_2_oMIBCAN: id 0x1B0000F5, to ABT_1_MIB_ab_Gen3, frame-length=8, can-addressing-mode=EXTENDED
        nm pdu NMH_DU_2_oMIBCAN: length=8, unused-bit-pattern=0
      frame NMH_Info_El_oMIBCAN: id 0x1B000073, to ABT_1_MIB_ab_Gen3, frame-length=8, can-addressing-mode=EXTENDED
        nm pdu NMH_Info_El_oMIBCAN: length=8, unused-bit-pattern=0
      frame NMH_LSR_1_oMIBCAN: id 0x1B0000F6, to ABT_1_MIB_ab_Gen3, frame-length=8, can-addressing-mode=EXTENDED
        nm pdu NMH_LSR_1_oMIBCAN: length=8, unused-bit-pattern=0
      frame NMH_WLC1_oMIBCAN: id 0x1B0000A5, to ABT_1_MIB_ab_Gen3, frame-length=8, can-addressing-mode=EXTENDED
        nm pdu NMH_WLC1_oMIBCAN: length=8, unused-bit-pattern=0
      frame OBDC_SSN_ABT_1_Req_oMIBCAN: id 0x17FC700E, to ABT_1_MIB_ab_Gen3, frame-length=8, can-addressing-mode=EXTENDED
        n pdu OBDC_SSN_ABT_1_Req_Tp_oMIBCAN: length=8
      frame OBDC_SSN_ABT_1_Resp_oMIBCAN: id 0x17FE700E, from ABT_1_MIB_ab_Gen3, frame-length=8, can-addressing-mode=EXTENDED
        n pdu OBDC_SSN_ABT_1_Resp_Tp_oMIBCAN: length=8
      frame ORU_01_oMIBCAN: id 0x1A555548, to ABT_1_MIB_ab_Gen3, frame-length=8, can-addressing-mode=EXTENDED
        pdu ORU_01_oMIBCAN:
          length=8
          minimum-delay=0.1
          transmission-mode-false-timing={cyclic-timing={time-offset=0, time-period=0.5}, event-controlled-timing={number-of-repetitions=0, repetition-period=0}}
          transmission-mode-true-timing={cyclic-timing={time-offset=0, time-period=0.5}, event-controlled-timing={number-of-repetitions=0, repetition-period=0}}
          variation-point=post-build-variant-condition{matching-criterion=Communication, value=0}
          minimum-delay=0
          transmission-mode-false-timing=event-controlled-timing={number-of-repetitions=0, repetition-period=0}
          transmission-mode-true-timing=event-controlled-timing={number-of-repetitions=0, repetition-period=0}
          variation-point=post-build-variant-condition{matching-criterion=Communication, value=1}
          unused-bit-pattern=0
          signal ORU_Status_oORU_01_oMIBCAN: start 61, 3 bit, little-endian, i-signal-type=PRIMITIVE, init-value=0, base-type=uint8, compu-method=CM_ORU_Status, data-constr=DC_ORU_Status, transfer-property=TRIGGERED-ON-CHANGE-WITHOUT-REPETITION, variation-point=post-build-variant-condition{matching-criterion=Communication, value=0}, to ABT_1_MIB_ab_Gen3  # Verteilung des internen ORU Zustandes
          signal ORU_01_CRC_oORU_01_oMIBCAN: start 0, 8 bit, little-endian, i-signal-type=PRIMITIVE, init-value=0, base-type=uint8, compu-method=CM_ORU_01_CRC, data-constr=DC_ORU_01_CRC, transfer-property=TRIGGERED-WITHOUT-REPETITION, variation-point=post-build-variant-condition{matching-criterion=Communication, value=1}, to ABT_1_MIB_ab_Gen3
          signal ORU_01_BZ_oORU_01_oMIBCAN: start 8, 4 bit, little-endian, i-signal-type=PRIMITIVE, init-value=0, base-type=uint8, compu-method=CM_ORU_01_BZ, data-constr=DC_ORU_01_BZ, transfer-property=TRIGGERED-WITHOUT-REPETITION, variation-point=post-build-variant-condition{matching-criterion=Communication, value=1}, to ABT_1_MIB_ab_Gen3
          signal ORU_DiagAddress_oORU_01_oMIBCAN: start 12, 16 bit, little-endian, i-signal-type=PRIMITIVE, init-value=0, base-type=uint16, compu-method=CM_ORU_DiagAddress, data-constr=DC_ORU_DiagAddress, transfer-property=PENDING, variation-point=post-build-variant-condition{matching-criterion=Communication, value=1}, to ABT_1_MIB_ab_Gen3  # Diagnostic address of next ECU to be updated
          signal ORU_01_0x1C_0x07_oORU_01_oMIBCAN: start 28, 7 bit, little-endian, i-signal-type=PRIMITIVE, base-type=uint8, variation-point=post-build-variant-condition{matching-criterion=Communication, value=1}, to ABT_1_MIB_ab_Gen3
          signal ORU_Inventory_oORU_01_oMIBCAN: start 35, 2 bit, little-endian, i-signal-type=PRIMITIVE, init-value=0, base-type=uint8, compu-method=CM_ORU_Inventory, data-constr=DC_ORU_Inventory, transfer-property=PENDING, variation-point=post-build-variant-condition{matching-criterion=Communication, value=1}, to ABT_1_MIB_ab_Gen3  # Signal zur Anzeige, ob die Inventory Erstellung durch ORU aktiv ist. 0 = Init 1 = ORU Inventory Erstellung ist nicht aktiv 2 = ORU Inventory Erstellung ist aktiv
          signal ORU_EM_Anfrage_freigegebeneNetze_oORU_01_oMIBCAN: start 37, 2 bit, little-endian, i-signal-type=PRIMITIVE, init-value=0, base-type=uint8, compu-method=CM_ORU_EM_Anfrage_freigegebeneNetze, data-constr=DC_ORU_EM_Anfrage_freigegebeneNetze, transfer-property=PENDING, variation-point=post-build-variant-condition{matching-criterion=Communication, value=1}, to ABT_1_MIB_ab_Gen3  # Meldung der wÃ¤hrend eines konkreten Online Remote Updates freigegebenen Netze (12V, 48V, HV)
          signal ORU_EM_Anfrage_Stromaufnahme_oORU_01_oMIBCAN: start 39, 9 bit, little-endian, i-signal-type=PRIMITIVE, init-value=0, base-type=uint16, compu-method=CM_ORU_EM_Anfrage_Stromaufnahme, data-constr=DC_ORU_EM_Anfrage_Stromaufnahme, unit=Unit_Amper, transfer-property=PENDING, variation-point=post-build-variant-condition{matching-criterion=Communication, value=1}, to ABT_1_MIB_ab_Gen3  # Meldung der voraussichtlichen durchschnittlichen Stromaufnahme eines konkreten Online Remote Updates an das NVEM
          signal ORU_EM_Anfrage_Flashdauer_oORU_01_oMIBCAN: start 48, 10 bit, little-endian, i-signal-type=PRIMITIVE, init-value=0, base-type=uint16, compu-method=CM_ORU_EM_Anfrage_Flashdauer, data-constr=DC_ORU_EM_Anfrage_Flashdauer, unit=Unit_Secon, transfer-property=PENDING, variation-point=post-build-variant-condition{matching-criterion=Communication, value=1}, to ABT_1_MIB_ab_Gen3  # Anfrage an das Energiemanagement, ob ein konkretes Online Remote Update durchgefÃ¼hrt werden kann - Flashdauer in 10s.
          signal ORU_Warnung_oORU_01_oMIBCAN: start 58, 2 bit, little-endian, i-signal-type=PRIMITIVE, init-value=0, base-type=uint8, compu-method=CM_ORU_Warnung, data-constr=DC_ORU_Warnung, transfer-property=PENDING, variation-point=post-build-variant-condition{matching-criterion=Communication, value=1}, to ABT_1_MIB_ab_Gen3  # Wenn durch StÃ¶rungen der Funktion Online Remote Update nicht sichergestellt ist, dass vor Kunde keine FunktionseinschrÃ¤nkungen auftreten, muss der Benutzer des Fahrzeugs entsprechend gewarnt werden.
          signal ORU_01_0x3C_0x01_oORU_01_oMIBCAN: start 60, 1 bit, little-endian, i-signal-type=PRIMITIVE, base-type=boolean, variation-point=post-build-variant-condition{matching-criterion=Communication, value=1}, to ABT_1_MIB_ab_Gen3
          signal ORU_Status_oORU_01_oMIBCAN: start 61, 3 bit, little-endian, i-signal-type=PRIMITIVE, init-value=0, base-type=uint8, compu-method=CM_ORU_Status, data-constr=DC_ORU_Status, transfer-property=PENDING, variation-point=post-build-variant-condition{matching-criterion=Communication, value=1}, to ABT_1_MIB_ab_Gen3  # Verteilung des internen ORU Zustandes
          mapping SG_ORU_01: i-signal-group=SG_ORU_01_oORU_01_oMIBCAN, transfer-property=PENDING, variation-point=post-build-variant-condition{matching-criterion=Communication, value=1}
      frame Systeminfo_01_oMIBCAN: id 0x585, to ABT_1_MIB_ab_Gen3, frame-length=8, can-addressing-mode=STANDARD  # MQB, MLBevo
        pdu Systeminfo_01_oMIBCAN: length=8, minimum-delay=0.01, transmission-mode-false-timing={cyclic-timing={time-offset=0, time-period=1}, event-controlled-timing={number-of-repetitions=0, repetition-period=0}}, transmission-mode-true-timing={cyclic-timing={time-offset=0, time-period=1}, event-controlled-timing={number-of-repetitions=0, repetition-period=0}}, unused-bit-pattern=0
          signal SI_T_Mode_oSysteminfo_01_oMIBCAN: start 9, 1 bit, little-endian, i-signal-type=PRIMITIVE, init-value=0, base-type=boolean, compu-method=CM_SI_T_Mode, data-constr=DC_SI_T_Mode, transfer-property=TRIGGERED-ON-CHANGE-WITHOUT-REPETITION, to ABT_1_MIB_ab_Gen3(timeout 5 s)  # 0x0: Transportmodus nicht aktiv 0x1: Transportmodus aktiv
          signal SI_BUS_03_oSysteminfo_01_oMIBCAN: start 18, 1 bit, little-endian, i-signal-type=PRIMITIVE, init-value=1, base-type=boolean, compu-method=CM_SI_BUS_03, data-constr=DC_SI_BUS_03, transfer-property=TRIGGERED-ON-CHANGE-WITHOUT-REPETITION, to ABT_1_MIB_ab_Gen3(timeout 5 s)  # MQB/MQB A0/PQ26: KCAN MQB2020: KCAN MLBevo: KCAN E3_Volumen: KCAN(HS) / K2CAN(FD) (Buskopplung) MQBw_Baseline: KCAN(HS)
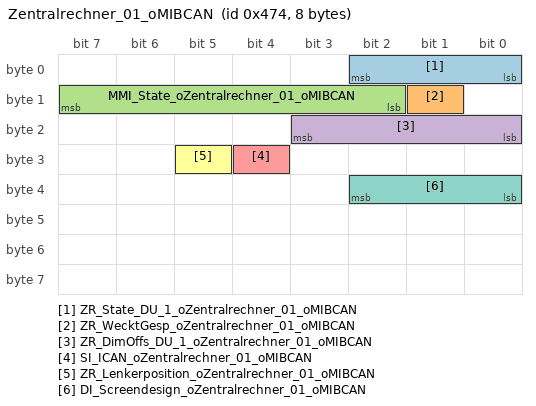
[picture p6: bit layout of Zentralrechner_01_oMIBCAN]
      frame Zentralrechner_01_oMIBCAN: id 0x474, to ABT_1_MIB_ab_Gen3, frame-length=8, can-addressing-mode=STANDARD
        pdu Zentralrechner_01_oMIBCAN: length=8, minimum-delay=0.04, transmission-mode-false-timing={cyclic-timing={time-offset=0, time-period=1}, event-controlled-timing={number-of-repetitions=0, repetition-period=0}}, transmission-mode-true-timing={cyclic-timing={time-offset=0, time-period=1}, event-controlled-timing={number-of-repetitions=0, repetition-period=0}}, unused-bit-pattern=0
          signal ZR_State_DU_1_oZentralrechner_01_oMIBCAN: start 0, 3 bit, little-endian, i-signal-type=PRIMITIVE, init-value=0, base-type=uint8, compu-method=CM_ZR_State_DU_1, data-constr=DC_ZR_State_DU_1, transfer-property=TRIGGERED-ON-CHANGE-WITHOUT-REPETITION, to ABT_1_MIB_ab_Gen3(timeout 5 s)  # Kontrollbit für Display, Hintergrundbeleuchtung aus, Hintergrundbeleuchtung an, Energiesparmodus.
          signal ZR_WecktGesp_oZentralrechner_01_oMIBCAN: start 9, 1 bit, little-endian, i-signal-type=PRIMITIVE, init-value=0, base-type=boolean, compu-method=CM_ZR_WecktGesp, data-constr=DC_ZR_WecktGesp, transfer-property=TRIGGERED-ON-CHANGE-WITHOUT-REPETITION, to ABT_1_MIB_ab_Gen3(timeout 5 s)  # Befehl zum Sperren der Wecktasten am Bedienteil.
          signal MMI_State_oZentralrechner_01_oMIBCAN: start 10, 6 bit, little-endian, i-signal-type=PRIMITIVE, init-value=0, base-type=uint8, compu-method=CM_MMI_State, data-constr=DC_MMI_State, transfer-property=TRIGGERED-ON-CHANGE-WITHOUT-REPETITION, to ABT_1_MIB_ab_Gen3(timeout 5 s)  # Powerstate des Zentralrechners. MMI_Off wird im Zustand dead mode gesendet.
          signal ZR_DimOffs_DU_1_oZentralrechner_01_oMIBCAN: start 16, 4 bit, little-endian, i-signal-type=PRIMITIVE, init-value=14, base-type=uint8, compu-method=CM_ZR_DimOffs_DU_1, data-constr=DC_ZR_DimOffs_DU_1, unit=Unit_None, transfer-property=TRIGGERED-ON-CHANGE-WITHOUT-REPETITION, to ABT_1_MIB_ab_Gen3(timeout 5 s)  # Dimmungs-Offset der Display Unit.
          signal SI_ICAN_oZentralrechner_01_oMIBCAN: start 28, 1 bit, little-endian, i-signal-type=PRIMITIVE, init-value=1, base-type=boolean, compu-method=CM_SI_ICAN, data-constr=DC_SI_ICAN, transfer-property=TRIGGERED-ON-CHANGE-WITHOUT-REPETITION, to ABT_1_MIB_ab_Gen3(timeout 5 s)  # MQB: Busruhe ICAN. E3: Busruhe ABCAN.
          signal ZR_Lenkerposition_oZentralrechner_01_oMIBCAN: start 29, 1 bit, little-endian, i-signal-type=PRIMITIVE, init-value=0, base-type=boolean, compu-method=CM_ZR_Lenkerposition, data-constr=DC_ZR_Lenkerposition, transfer-property=PENDING, to ABT_1_MIB_ab_Gen3(timeout 5 s)  # Ueber Diagnose (Codierung) im Zentralrechner eingespeicherte Lenkerposition
          signal DI_Screendesign_oZentralrechner_01_oMIBCAN: start 32, 3 bit, little-endian, i-signal-type=PRIMITIVE, init-value=6, base-type=uint8, compu-method=CM_DI_Screendesign, data-constr=DC_DI_Screendesign, transfer-property=TRIGGERED-ON-CHANGE-WITHOUT-REPETITION, to ABT_1_MIB_ab_Gen3(timeout 5 s)  # Information welcher Designwunsch ausgewählt wurde zur Kennlinienumschaltung
      frame Zentralrechner_04_oMIBCAN: id 0x1A55567D, to ABT_1_MIB_ab_Gen3, frame-length=8, can-addressing-mode=EXTENDED
        pdu Zentralrechner_04_oMIBCAN: length=8, minimum-delay=0.1, transmission-mode-false-timing={cyclic-timing={time-offset=0, time-period=0.5}, event-controlled-timing={number-of-repetitions=0, repetition-period=0}}, transmission-mode-true-timing={cyclic-timing={time-offset=0, time-period=0.5}, event-controlled-timing={number-of-repetitions=0, repetition-period=0}}, unused-bit-pattern=0
          signal ZR_Plattform_oZentralrechner_04_oMIBCAN: start 12, 5 bit, little-endian, i-signal-type=PRIMITIVE, init-value=0, base-type=uint8, compu-method=CM_ZR_Plattform, data-constr=DC_ZR_Plattform, transfer-property=TRIGGERED-ON-CHANGE-WITHOUT-REPETITION, to ABT_1_MIB_ab_Gen3(timeout 5 s)  # Fahrzeug-Plattform (vom Zentralrechner am I-CAN bzw. AB-CAN genutzte Datenfestlegungsversion)
      frame NMH_DU_3_oMIBCAN: id 0x1B0000FE, to ABT_1_MIB_ab_Gen3, frame-length=8, variation-point=post-build-variant-condition{matching-criterion=Communication, value=1}, can-addressing-mode=EXTENDED
        nm pdu NMH_DU_3_oMIBCAN: length=8, unused-bit-pattern=0
      pdu triggering PT_DEV_ABT_1_Req_04: pdu=DEV_ABT_1_Req_04_oMIBCAN, to ABT_1_MIB_ab_Gen3
      pdu triggering PT_DEV_ABT_1_Resp_04: pdu=DEV_ABT_1_Resp_04_oMIBCAN, from ABT_1_MIB_ab_Gen3
      pdu triggering PT_DIA_ABT_1_Req: pdu=DIA_ABT_1_Req_oMIBCAN, to ABT_1_MIB_ab_Gen3
      pdu triggering PT_DIA_ABT_1_Resp: pdu=DIA_ABT_1_Resp_oMIBCAN, from ABT_1_MIB_ab_Gen3
      pdu triggering PT_Diag_ABT_1_Req: pdu=Diag_ABT_1_Req_oMIBCAN, to ABT_1_MIB_ab_Gen3
      pdu triggering PT_Diag_ABT_1_Resp: pdu=Diag_ABT_1_Resp_oMIBCAN, from ABT_1_MIB_ab_Gen3
      pdu triggering PT_HID_ABT_1_ZR_Req: pdu=HID_ABT_1_ZR_Req_oMIBCAN, from ABT_1_MIB_ab_Gen3
      pdu triggering PT_HID_ABT_1_ZR_Resp: pdu=HID_ABT_1_ZR_Resp_oMIBCAN, to ABT_1_MIB_ab_Gen3
      pdu triggering PT_HID_ZR_ABT_1_Req: pdu=HID_ZR_ABT_1_Req_oMIBCAN, to ABT_1_MIB_ab_Gen3
      pdu triggering PT_HID_ZR_ABT_1_Resp: pdu=HID_ZR_ABT_1_Resp_oMIBCAN, from ABT_1_MIB_ab_Gen3
      pdu triggering PT_KS_SSN_ABT_1_Req: pdu=KS_SSN_ABT_1_Req_oMIBCAN, to ABT_1_MIB_ab_Gen3
      pdu triggering PT_KS_SSN_ABT_1_Resp: pdu=KS_SSN_ABT_1_Resp_oMIBCAN, from ABT_1_MIB_ab_Gen3
      pdu triggering PT_OBDC_SSN_ABT_1_Req: pdu=OBDC_SSN_ABT_1_Req_oMIBCAN, to ABT_1_MIB_ab_Gen3
      pdu triggering PT_OBDC_SSN_ABT_1_Resp: pdu=OBDC_SSN_ABT_1_Resp_oMIBCAN, from ABT_1_MIB_ab_Gen3
package /ECU
  ecu instance ABT_1_MIB_ab_Gen3: associated-com-i-pdu-group=[ABT_1_MIB_ab_Gen3_oMIBCAN_Rx, ABT_1_MIB_ab_Gen3_oMIBCAN_Tx]
    can communication controller CT_MIBCAN: can-controller-attributes=can-controller-configuration-requirements={max-number-of-time-quanta-per-bit=20, max-sample-point=84, max-sync-jump-width=20, min-number-of-time-quanta-per-bit=10, min-sample-point=80, min-sync-jump-width=20}
    can communication connector CN_MIBCAN: comm-controller=CT_MIBCAN
package /IPDUGroup
  i signal i pdu group ABT_1_MIB_ab_Gen3_oMIBCAN_Rx: communication-direction=IN
    i-signal-i-pdus:
      BEM_02_oMIBCAN
      Diagnose_01_oMIBCAN
      Dimmung_01_oMIBCAN
      Klemmen_Status_01_oMIBCAN
      ORU_01_oMIBCAN
      Systeminfo_01_oMIBCAN
      Zentralrechner_01_oMIBCAN
      Zentralrechner_04_oMIBCAN
  i signal i pdu group ABT_1_MIB_ab_Gen3_oMIBCAN_Tx: communication-direction=OUT, i-signal-i-pdus=[Display_1_01_oMIBCAN, Display_1_02_oMIBCAN, Display_1_03_oMIBCAN]
package /PDU
  dcm i pdu DEV_ABT_1_Req_04_oMIBCAN: length=8, diag-pdu-type=DIAG-REQUEST
  dcm i pdu DEV_ABT_1_Resp_04_oMIBCAN: length=8, diag-pdu-type=DIAG-RESPONSE
  dcm i pdu DIA_ABT_1_Req_oMIBCAN: length=8, diag-pdu-type=DIAG-REQUEST
  dcm i pdu DIA_ABT_1_Resp_oMIBCAN: length=8, diag-pdu-type=DIAG-RESPONSE
  dcm i pdu Diag_ABT_1_Req_oMIBCAN: length=8, diag-pdu-type=DIAG-REQUEST
  dcm i pdu Diag_ABT_1_Resp_oMIBCAN: length=8, diag-pdu-type=DIAG-RESPONSE
  dcm i pdu HID_ABT_1_ZR_Req_oMIBCAN: length=8, diag-pdu-type=DIAG-REQUEST
  dcm i pdu HID_ABT_1_ZR_Resp_oMIBCAN: length=8, diag-pdu-type=DIAG-RESPONSE
  dcm i pdu HID_ZR_ABT_1_Req_oMIBCAN: length=8, diag-pdu-type=DIAG-REQUEST
  dcm i pdu HID_ZR_ABT_1_Resp_oMIBCAN: length=8, diag-pdu-type=DIAG-RESPONSE
  dcm i pdu KS_SSN_ABT_1_Req_oMIBCAN: length=8, diag-pdu-type=DIAG-REQUEST
  dcm i pdu KS_SSN_ABT_1_Resp_oMIBCAN: length=8, diag-pdu-type=DIAG-RESPONSE
  dcm i pdu OBDC_SSN_ABT_1_Req_oMIBCAN: length=8, diag-pdu-type=DIAG-REQUEST
  dcm i pdu OBDC_SSN_ABT_1_Resp_oMIBCAN: length=8, diag-pdu-type=DIAG-RESPONSE
package /ISignal
  i signal group SG_Klemmen_Status_01_oKlemmen_Status_01_oMIBCAN:
    variation-point=post-build-variant-condition{matching-criterion=Communication, value=0}
    i-signal=[BCM_Ausparken_Betrieb_oKlemmen_Status_01_oMIBCAN, BCM_Remotestart_Betrieb_oKlemmen_Status_01_oMIBCAN, BCM_Remotestart_KL15_Anf_oKlemmen_Status_01_oMIBCAN, BCM_Remotestart_MO_Start_oKlemmen_Status_01_oMIBCAN, Klemmen_Status_01_BZ_oKlemmen_Status_01_oMIBCAN, Klemmen_Status_01_CRC_oKlemmen_Status_01_oMIBCAN, KST_Fahrerhinweis_1_oKlemmen_Status_01_oMIBCAN, KST_Fahrerhinweis_2_oKlemmen_Status_01_oMIBCAN, KST_Fahrerhinweis_4_oKlemmen_Status_01_oMIBCAN, KST_Fahrerhinweis_5_oKlemmen_Status_01_oMIBCAN, KST_Fahrerhinweis_6_oKlemmen_Status_01_oMIBCAN, KST_Warn_P1_ZST_def_oKlemmen_Status_01_oMIBCAN, KST_Warn_P2_ZST_def_oKlemmen_Status_01_oMIBCAN, RSt_Fahrerhinweise_oKlemmen_Status_01_oMIBCAN, ZAS_Kl_15_oKlemmen_Status_01_oMIBCAN, ZAS_Kl_50_Startanforderung_oKlemmen_Status_01_oMIBCAN, ZAS_Kl_Infotainment_oKlemmen_Status_01_oMIBCAN, ZAS_Kl_S_oKlemmen_Status_01_oMIBCAN, ZAS_Kl_X_oKlemmen_Status_01_oMIBCAN]
    system-signal-group=Signal/SG_Klemmen_Status_01
  i signal group SG_Klemmen_Status_01_oKlemmen_Status_01_oMIBCAN:
    variation-point=post-build-variant-condition{matching-criterion=Communication, value=1}
    i-signal=[BCM_Ausparken_Betrieb_oKlemmen_Status_01_oMIBCAN, Klemmen_Status_01_0x14_0x01_oKlemmen_Status_01_oMIBCAN, Klemmen_Status_01_0x16_0x02_oKlemmen_Status_01_oMIBCAN, Klemmen_Status_01_BZ_oKlemmen_Status_01_oMIBCAN, Klemmen_Status_01_CRC_oKlemmen_Status_01_oMIBCAN, KST_Fahrerhinweis_1_oKlemmen_Status_01_oMIBCAN, KST_Fahrerhinweis_2_oKlemmen_Status_01_oMIBCAN, KST_Fahrerhinweis_4_oKlemmen_Status_01_oMIBCAN, KST_Fahrerhinweis_5_oKlemmen_Status_01_oMIBCAN, KST_Fahrerhinweis_6_oKlemmen_Status_01_oMIBCAN, KST_Warn_P1_ZST_def_oKlemmen_Status_01_oMIBCAN, KST_Warn_P2_ZST_def_oKlemmen_Status_01_oMIBCAN, RSt_Fahrerhinweise_oKlemmen_Status_01_oMIBCAN, ZAS_Kl_15_oKlemmen_Status_01_oMIBCAN, ZAS_Kl_50_Startanforderung_oKlemmen_Status_01_oMIBCAN, ZAS_Kl_Infotainment_oKlemmen_Status_01_oMIBCAN, ZAS_Kl_S_oKlemmen_Status_01_oMIBCAN, ZAS_Kl_X_oKlemmen_Status_01_oMIBCAN]
    system-signal-group=Signal/SG_Klemmen_Status_01
  i signal group SG_ORU_01_oORU_01_oMIBCAN: i-signal=[ORU_01_0x1C_0x07_oORU_01_oMIBCAN, ORU_01_0x3C_0x01_oORU_01_oMIBCAN, ORU_01_BZ_oORU_01_oMIBCAN, ORU_01_CRC_oORU_01_oMIBCAN, ORU_DiagAddress_oORU_01_oMIBCAN, ORU_EM_Anfrage_Flashdauer_oORU_01_oMIBCAN, ORU_EM_Anfrage_freigegebeneNetze_oORU_01_oMIBCAN, ORU_EM_Anfrage_Stromaufnahme_oORU_01_oMIBCAN, ORU_Inventory_oORU_01_oMIBCAN, ORU_Status_oORU_01_oMIBCAN, ORU_Warnung_oORU_01_oMIBCAN], system-signal-group=SG_ORU_01
package /Signal
  system signal group SG_Klemmen_Status_01: variation-point=post-build-variant-condition{matching-criterion=Communication, value=0}, system-signal=[BCM_Ausparken_Betrieb, BCM_Remotestart_Betrieb, BCM_Remotestart_KL15_Anf, BCM_Remotestart_MO_Start, Klemmen_Status_01_BZ, Klemmen_Status_01_CRC, KST_Fahrerhinweis_1, KST_Fahrerhinweis_2, KST_Fahrerhinweis_4, KST_Fahrerhinweis_5, KST_Fahrerhinweis_6, KST_Warn_P1_ZST_def, KST_Warn_P2_ZST_def, RSt_Fahrerhinweise, ZAS_Kl_15, ZAS_Kl_50_Startanforderung, ZAS_Kl_Infotainment, ZAS_Kl_S, ZAS_Kl_X]  # Pdu signal group
  system signal group SG_Klemmen_Status_01: variation-point=post-build-variant-condition{matching-criterion=Communication, value=1}, system-signal=[BCM_Ausparken_Betrieb, Klemmen_Status_01_0x14_0x01, Klemmen_Status_01_0x16_0x02, Klemmen_Status_01_BZ, Klemmen_Status_01_CRC, KST_Fahrerhinweis_1, KST_Fahrerhinweis_2, KST_Fahrerhinweis_4, KST_Fahrerhinweis_5, KST_Fahrerhinweis_6, KST_Warn_P1_ZST_def, KST_Warn_P2_ZST_def, RSt_Fahrerhinweise, ZAS_Kl_15, ZAS_Kl_50_Startanforderung, ZAS_Kl_Infotainment, ZAS_Kl_S, ZAS_Kl_X]  # Pdu signal group
  system signal group SG_ORU_01: system-signal=[ORU_01_0x1C_0x07, ORU_01_0x3C_0x01, ORU_01_BZ, ORU_01_CRC, ORU_DiagAddress, ORU_EM_Anfrage_Flashdauer, ORU_EM_Anfrage_freigegebeneNetze, ORU_EM_Anfrage_Stromaufnahme, ORU_Inventory, ORU_Status, ORU_Warnung]  # Pdu signal group
